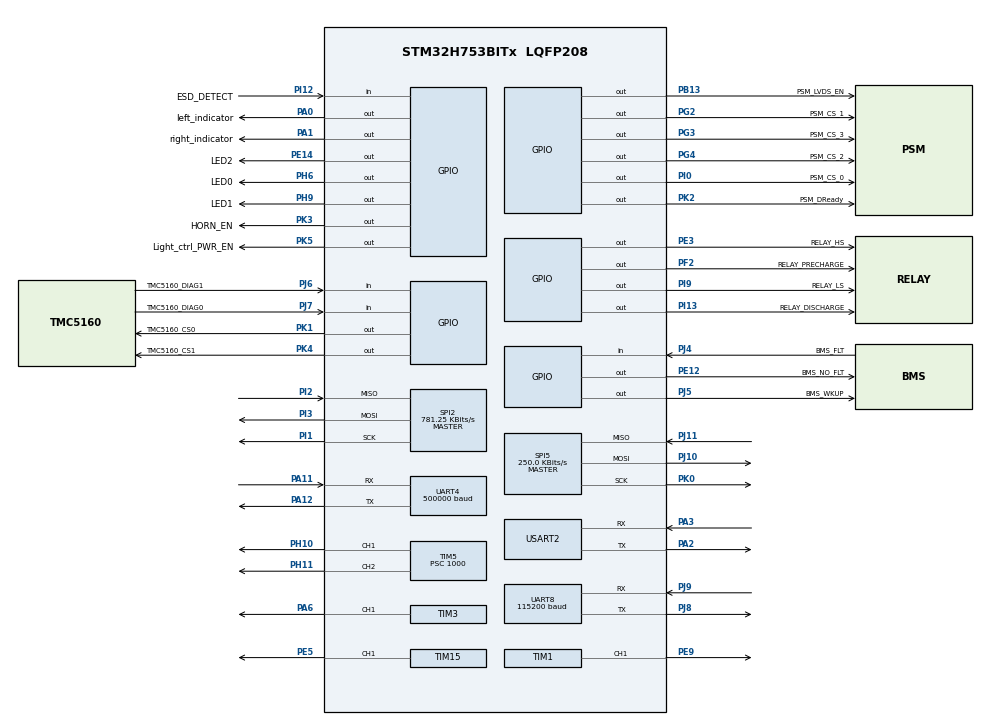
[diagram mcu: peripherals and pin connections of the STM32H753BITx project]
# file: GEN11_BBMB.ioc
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CRC.InputDataFormat=CRC_INPUTDATA_FORMAT_WORDS
CRC.InputDataInversionMode=CRC_INPUTDATA_INVERSION_NONE
CRC.OutputDataInversionMode=CRC_OUTPUTDATA_INVERSION_DISABLE
Dma.Request0=UART4_RX
Dma.Request1=UART4_TX
Dma.Request2=UART8_RX
Dma.Request3=UART8_TX
Dma.Request4=SPI2_RX
Dma.Request5=SPI2_TX
Dma.SPI2_RX.4.Direction=DMA_PERIPH_TO_MEMORY
Dma.SPI2_RX.4.EventEnable=DISABLE
Dma.SPI2_RX.4.FIFOMode=DMA_FIFOMODE_DISABLE
Dma.SPI2_RX.4.Instance=DMA1_Stream4
Dma.SPI2_RX.4.MemDataAlignment=DMA_MDATAALIGN_BYTE
Dma.SPI2_RX.4.MemInc=DMA_MINC_ENABLE
Dma.SPI2_RX.4.Mode=DMA_NORMAL
Dma.SPI2_RX.4.PeriphDataAlignment=DMA_PDATAALIGN_BYTE
Dma.SPI2_RX.4.PeriphInc=DMA_PINC_DISABLE
Dma.SPI2_RX.4.Polarity=HAL_DMAMUX_REQ_GEN_RISING
Dma.SPI2_RX.4.Priority=DMA_PRIORITY_LOW
Dma.SPI2_RX.4.RequestNumber=1
Dma.SPI2_RX.4.SignalID=NONE
Dma.SPI2_RX.4.SyncEnable=DISABLE
Dma.SPI2_RX.4.SyncPolarity=HAL_DMAMUX_SYNC_NO_EVENT
Dma.SPI2_RX.4.SyncRequestNumber=1
Dma.SPI2_RX.4.SyncSignalID=NONE
Dma.SPI2_TX.5.Direction=DMA_MEMORY_TO_PERIPH
Dma.SPI2_TX.5.EventEnable=DISABLE
Dma.SPI2_TX.5.FIFOMode=DMA_FIFOMODE_DISABLE
Dma.SPI2_TX.5.Instance=DMA1_Stream5
Dma.SPI2_TX.5.MemDataAlignment=DMA_MDATAALIGN_BYTE
Dma.SPI2_TX.5.MemInc=DMA_MINC_ENABLE
Dma.SPI2_TX.5.Mode=DMA_NORMAL
Dma.SPI2_TX.5.PeriphDataAlignment=DMA_PDATAALIGN_BYTE
Dma.SPI2_TX.5.PeriphInc=DMA_PINC_DISABLE
Dma.SPI2_TX.5.Polarity=HAL_DMAMUX_REQ_GEN_RISING
Dma.SPI2_TX.5.Priority=DMA_PRIORITY_LOW
Dma.SPI2_TX.5.RequestNumber=1
Dma.SPI2_TX.5.SignalID=NONE
Dma.SPI2_TX.5.SyncEnable=DISABLE
Dma.SPI2_TX.5.SyncPolarity=HAL_DMAMUX_SYNC_NO_EVENT
Dma.SPI2_TX.5.SyncRequestNumber=1
Dma.SPI2_TX.5.SyncSignalID=NONE
Dma.UART4_RX.0.Direction=DMA_PERIPH_TO_MEMORY
Dma.UART4_RX.0.EventEnable=DISABLE
Dma.UART4_RX.0.FIFOMode=DMA_FIFOMODE_DISABLE
Dma.UART4_RX.0.Instance=DMA1_Stream0
Dma.UART4_RX.0.MemDataAlignment=DMA_MDATAALIGN_BYTE
Dma.UART4_RX.0.MemInc=DMA_MINC_ENABLE
Dma.UART4_RX.0.Mode=DMA_CIRCULAR
Dma.UART4_RX.0.PeriphDataAlignment=DMA_PDATAALIGN_BYTE
Dma.UART4_RX.0.PeriphInc=DMA_PINC_DISABLE
Dma.UART4_RX.0.Polarity=HAL_DMAMUX_REQ_GEN_RISING
Dma.UART4_RX.0.Priority=DMA_PRIORITY_HIGH
Dma.UART4_RX.0.RequestNumber=1
Dma.UART4_RX.0.SignalID=NONE
Dma.UART4_RX.0.SyncEnable=DISABLE
Dma.UART4_RX.0.SyncPolarity=HAL_DMAMUX_SYNC_NO_EVENT
Dma.UART4_RX.0.SyncRequestNumber=1
Dma.UART4_RX.0.SyncSignalID=NONE
Dma.UART4_TX.1.Direction=DMA_MEMORY_TO_PERIPH
Dma.UART4_TX.1.EventEnable=DISABLE
Dma.UART4_TX.1.FIFOMode=DMA_FIFOMODE_DISABLE
Dma.UART4_TX.1.Instance=DMA1_Stream1
Dma.UART4_TX.1.MemDataAlignment=DMA_MDATAALIGN_BYTE
Dma.UART4_TX.1.MemInc=DMA_MINC_ENABLE
Dma.UART4_TX.1.Mode=DMA_NORMAL
Dma.UART4_TX.1.PeriphDataAlignment=DMA_PDATAALIGN_BYTE
Dma.UART4_TX.1.PeriphInc=DMA_PINC_DISABLE
Dma.UART4_TX.1.Polarity=HAL_DMAMUX_REQ_GEN_RISING
Dma.UART4_TX.1.Priority=DMA_PRIORITY_MEDIUM
Dma.UART4_TX.1.RequestNumber=1
Dma.UART4_TX.1.SignalID=NONE
Dma.UART4_TX.1.SyncEnable=DISABLE
Dma.UART4_TX.1.SyncPolarity=HAL_DMAMUX_SYNC_NO_EVENT
Dma.UART4_TX.1.SyncRequestNumber=1
Dma.UART4_TX.1.SyncSignalID=NONE
Dma.UART8_RX.2.Direction=DMA_PERIPH_TO_MEMORY
Dma.UART8_RX.2.EventEnable=DISABLE
Dma.UART8_RX.2.FIFOMode=DMA_FIFOMODE_DISABLE
Dma.UART8_RX.2.Instance=DMA1_Stream2
Dma.UART8_RX.2.MemDataAlignment=DMA_MDATAALIGN_BYTE
Dma.UART8_RX.2.MemInc=DMA_MINC_ENABLE
Dma.UART8_RX.2.Mode=DMA_CIRCULAR
Dma.UART8_RX.2.PeriphDataAlignment=DMA_PDATAALIGN_BYTE
Dma.UART8_RX.2.PeriphInc=DMA_PINC_DISABLE
Dma.UART8_RX.2.Polarity=HAL_DMAMUX_REQ_GEN_RISING
Dma.UART8_RX.2.Priority=DMA_PRIORITY_HIGH
Dma.UART8_RX.2.RequestNumber=1
Dma.UART8_RX.2.SignalID=NONE
Dma.UART8_RX.2.SyncEnable=DISABLE
Dma.UART8_RX.2.SyncPolarity=HAL_DMAMUX_SYNC_NO_EVENT
Dma.UART8_RX.2.SyncRequestNumber=1
Dma.UART8_RX.2.SyncSignalID=NONE
Dma.UART8_TX.3.Direction=DMA_MEMORY_TO_PERIPH
Dma.UART8_TX.3.EventEnable=DISABLE
Dma.UART8_TX.3.FIFOMode=DMA_FIFOMODE_DISABLE
Dma.UART8_TX.3.Instance=DMA1_Stream3
Dma.UART8_TX.3.MemDataAlignment=DMA_MDATAALIGN_BYTE
Dma.UART8_TX.3.MemInc=DMA_MINC_ENABLE
Dma.UART8_TX.3.Mode=DMA_NORMAL
Dma.UART8_TX.3.PeriphDataAlignment=DMA_PDATAALIGN_BYTE
Dma.UART8_TX.3.PeriphInc=DMA_PINC_DISABLE
Dma.UART8_TX.3.Polarity=HAL_DMAMUX_REQ_GEN_RISING
Dma.UART8_TX.3.Priority=DMA_PRIORITY_MEDIUM
Dma.UART8_TX.3.RequestNumber=1
Dma.UART8_TX.3.SignalID=NONE
Dma.UART8_TX.3.SyncEnable=DISABLE
Dma.UART8_TX.3.SyncPolarity=HAL_DMAMUX_SYNC_NO_EVENT
Dma.UART8_TX.3.SyncRequestNumber=1
Dma.UART8_TX.3.SyncSignalID=NONE
FREERTOS.INCLUDE_vTaskDelayUntil=1
FREERTOS.MEMORY_ALLOCATION=2
FREERTOS.Tasks01=defaultTask,0,128,StartDefaultTask,Default,NULL,Static,defaultTaskBuffer,defaultTaskControlBlock
FREERTOS.configTIMER_TASK_PRIORITY=5
FREERTOS.configTOTAL_HEAP_SIZE=40000
FREERTOS.configUSE_NEWLIB_REENTRANT=1
FREERTOS.configUSE_TIMERS=1
Mcu.Family=STM32H7
Mcu.Name=STM32H753BITx
Mcu.Package=LQFP208
NVIC.DMA1_Stream0_IRQn=true\:5\:0\:false\:false\:true\:true\:false\:true\:true
NVIC.DMA1_Stream1_IRQn=true\:5\:0\:false\:false\:true\:true\:false\:true\:true
NVIC.DMA1_Stream2_IRQn=true\:5\:0\:false\:false\:true\:true\:false\:true\:true
NVIC.DMA1_Stream3_IRQn=true\:5\:0\:false\:false\:true\:true\:false\:true\:true
NVIC.DMA1_Stream4_IRQn=true\:5\:0\:false\:false\:true\:true\:false\:true\:true
NVIC.DMA1_Stream5_IRQn=true\:5\:0\:false\:false\:true\:true\:false\:true\:true
NVIC.PriorityGroup=NVIC_PRIORITYGROUP_4
NVIC.SPI2_IRQn=true\:5\:0\:false\:false\:true\:true\:false\:true\:true
NVIC.SPI5_IRQn=true\:5\:0\:false\:false\:true\:true\:true\:true\:true
NVIC.TIM6_DAC_IRQn=true\:15\:0\:false\:false\:true\:false\:false\:true\:true
NVIC.TIM7_IRQn=true\:5\:0\:false\:false\:true\:true\:true\:true\:true
NVIC.TimeBase=TIM6_DAC_IRQn
NVIC.TimeBaseIP=TIM6
NVIC.UART4_IRQn=true\:5\:0\:false\:false\:true\:true\:true\:true\:true
NVIC.UART8_IRQn=true\:5\:0\:false\:false\:true\:true\:true\:true\:true
PA0.GPIO_Label=left_indicator
PA0.Signal=GPIO_Output
PA1.GPIO_Label=right_indicator
PA1.Signal=GPIO_Output
PA11.Mode=Asynchronous
PA11.Signal=UART4_RX
PA12.Mode=Asynchronous
PA12.Signal=UART4_TX
PA13\ (JTMS/SWDIO).Mode=Serial_Wire
PA13\ (JTMS/SWDIO).Signal=DEBUG_JTMS-SWDIO
PA14\ (JTCK/SWCLK).Mode=Serial_Wire
PA14\ (JTCK/SWCLK).Signal=DEBUG_JTCK-SWCLK
PA2.Mode=Asynchronous
PA2.Signal=USART2_TX
PA3.Mode=Asynchronous
PA3.Signal=USART2_RX
PA6.Signal=S_TIM3_CH1
PB13.GPIO_Label=PSM_LVDS_EN
PB13.Signal=GPIO_Output
PE12.GPIO_Label=BMS_NO_FLT
PE12.Signal=GPIO_Output
PE14.GPIO_Label=LED2
PE14.Signal=GPIO_Output
PE3.GPIO_Label=RELAY_HS
PE3.Signal=GPIO_Output
PE5.Signal=S_TIM15_CH1
PE9.Signal=S_TIM1_CH1
PF2.GPIO_Label=RELAY_PRECHARGE
PF2.Signal=GPIO_Output
PG2.GPIO_Label=PSM_CS_1
PG2.Signal=GPIO_Output
PG3.GPIO_Label=PSM_CS_3
PG3.Signal=GPIO_Output
PG4.GPIO_Label=PSM_CS_2
PG4.Signal=GPIO_Output
PH0-OSC_IN\ (PH0).Mode=HSE-External-Oscillator
PH0-OSC_IN\ (PH0).Signal=RCC_OSC_IN
PH1-OSC_OUT\ (PH1).Mode=HSE-External-Oscillator
PH1-OSC_OUT\ (PH1).Signal=RCC_OSC_OUT
PH10.Signal=S_TIM5_CH1
PH11.Signal=S_TIM5_CH2
PH6.GPIO_Label=LED0
PH6.Signal=GPIO_Output
PH9.GPIO_Label=LED1
PH9.Signal=GPIO_Output
PI0.GPIO_Label=PSM_CS_0
PI0.Signal=GPIO_Output
PI1.Mode=Full_Duplex_Master
PI1.Signal=SPI2_SCK
PI12.GPIO_Label=ESD_DETECT
PI12.Signal=GPIO_Input
PI13.GPIO_Label=RELAY_DISCHARGE
PI13.GPIO_PuPd=GPIO_PULLDOWN
PI13.Signal=GPIO_Output
PI2.Mode=Full_Duplex_Master
PI2.Signal=SPI2_MISO
PI3.Mode=Full_Duplex_Master
PI3.Signal=SPI2_MOSI
PI9.GPIO_Label=RELAY_LS
PI9.Signal=GPIO_Output
PJ10.Mode=Full_Duplex_Master
PJ10.Signal=SPI5_MOSI
PJ11.Mode=Full_Duplex_Master
PJ11.Signal=SPI5_MISO
PJ4.GPIO_Label=BMS_FLT
PJ4.Signal=GPIO_Input
PJ5.GPIO_Label=BMS_WKUP
PJ5.Signal=GPIO_Output
PJ6.GPIO_Label=TMC5160_DIAG1
PJ6.Signal=GPIO_Input
PJ7.GPIO_Label=TMC5160_DIAG0
PJ7.Signal=GPIO_Input
PJ8.Mode=Asynchronous
PJ8.Signal=UART8_TX
PJ9.Mode=Asynchronous
PJ9.Signal=UART8_RX
PK0.Mode=Full_Duplex_Master
PK0.Signal=SPI5_SCK
PK1.GPIO_Label=TMC5160_CS0
PK1.Signal=GPIO_Output
PK2.GPIO_Label=PSM_DReady
PK2.Signal=GPIO_Output
PK3.GPIO_Label=HORN_EN
PK3.GPIO_PuPd=GPIO_PULLDOWN
PK3.Signal=GPIO_Output
PK4.GPIO_Label=TMC5160_CS1
PK4.Signal=GPIO_Output
PK5.GPIO_Label=Light_ctrl_PWR_EN
PK5.Signal=GPIO_Output
ProjectManager.HeapSize=0x200
ProjectManager.StackSize=0x400
ProjectManager.TargetToolchain=STM32CubeIDE
RCC.ADCFreq_Value=50390625
RCC.APB1Freq_Value=16000000
RCC.APB2Freq_Value=16000000
RCC.APB3Freq_Value=32000000
RCC.APB4Freq_Value=32000000
RCC.CortexFreq_Value=64000000
RCC.D2PPRE1=RCC_APB1_DIV2
RCC.D2PPRE2=RCC_APB2_DIV2
RCC.DATA_CACHE_ENABLE=1
RCC.DIVM1=2
RCC.DIVN1=16
RCC.DIVQ1=4
RCC.HCLKFreq_Value=32000000
RCC.HPRE=RCC_HCLK_DIV2
RCC.HSE_VALUE=25000000
RCC.INSTRUCTION_CACHE_ENABLE=1
RCC.MSIAutoCalibration=DISABLED
RCC.MSICalibrationValue=0
RCC.PLL1_VCI_Range-AdvancedSettings=RCC_PLL1VCIRANGE_0
RCC.PLL2FRACN=0
RCC.PLL2_VCI_Range-AdvancedSettings=RCC_PLL2VCIRANGE_0
RCC.PLL3FRACN=0
RCC.PLLFRACN=0
RCC.PLLSourceVirtual=RCC_PLLSOURCE_HSE
RCC.PREFETCH_ENABLE=0
RCC.SYSCLKFreq_VALUE=64000000
RCC.USBFreq_Value=50000000
SH.S_TIM15_CH1.0=TIM15_CH1,PWM Generation1 CH1
SH.S_TIM1_CH1.0=TIM1_CH1,PWM Generation1 CH1
SH.S_TIM3_CH1.0=TIM3_CH1,PWM Generation1 CH1
SH.S_TIM5_CH1.0=TIM5_CH1,PWM Generation1 CH1
SH.S_TIM5_CH2.0=TIM5_CH2,PWM Generation2 CH2
SPI2.BaudRatePrescaler=SPI_BAUDRATEPRESCALER_64
SPI2.CLKPhase=SPI_PHASE_2EDGE
SPI2.CLKPolarity=SPI_POLARITY_LOW
SPI2.CalculateBaudRate=781.25 KBits/s
SPI2.DataSize=SPI_DATASIZE_8BIT
SPI2.Direction=SPI_DIRECTION_2LINES
SPI2.Mode=SPI_MODE_MASTER
SPI2.VirtualType=VM_MASTER
SPI5.BaudRatePrescaler=SPI_BAUDRATEPRESCALER_64
SPI5.CLKPhase=SPI_PHASE_2EDGE
SPI5.CLKPolarity=SPI_POLARITY_HIGH
SPI5.CalculateBaudRate=250.0 KBits/s
SPI5.DataSize=SPI_DATASIZE_8BIT
SPI5.Direction=SPI_DIRECTION_2LINES
SPI5.Mode=SPI_MODE_MASTER
SPI5.VirtualType=VM_MASTER
TIM1.AutoReloadPreload=TIM_AUTORELOAD_PRELOAD_ENABLE
TIM1.Channel-PWM\ Generation1\ CH1=TIM_CHANNEL_1
TIM1.Period=13552
TIM1.Prescaler=1000
TIM1.TIM_MasterOutputTrigger=TIM_TRGO_OC1REF
TIM15.Channel-PWM\ Generation1\ CH1=TIM_CHANNEL_1
TIM2.AutoReloadPreload=TIM_AUTORELOAD_PRELOAD_ENABLE
TIM2.Period=1600
TIM2.Prescaler=1000
TIM3.AutoReloadPreload=TIM_AUTORELOAD_PRELOAD_ENABLE
TIM3.Channel-PWM\ Generation1\ CH1=TIM_CHANNEL_1
TIM3.Period=6400
TIM3.Prescaler=1000
TIM3.Pulse-PWM\ Generation1\ CH1=0
TIM5.AutoReloadPreload=TIM_AUTORELOAD_PRELOAD_ENABLE
TIM5.Channel-PWM\ Generation1\ CH1=TIM_CHANNEL_1
TIM5.Channel-PWM\ Generation2\ CH2=TIM_CHANNEL_2
TIM5.Period=1600
TIM5.Prescaler=1000
TIM5.Pulse-PWM\ Generation1\ CH1=0
TIM7.AutoReloadPreload=TIM_AUTORELOAD_PRELOAD_ENABLE
TIM7.Period=1000
TIM7.Prescaler=40000
UART4.BaudRate=500000
UART8.BaudRate=115200
USART2.VirtualMode-Asynchronous=VM_ASYNC
VP_CRC_VS_CRC.Mode=CRC_Activate
VP_FREERTOS_VS_CMSIS_V1.Mode=CMSIS_V1
VP_SYS_VS_tim6.Mode=TIM6
VP_TIM2_VS_ClockSourceITR.Mode=TriggerSource_ITR0
VP_TIM2_VS_ControllerModeGated.Mode=Gated Mode
VP_TIM3_VS_ClockSourceITR.Mode=TriggerSource_ITR2
VP_TIM3_VS_ControllerModeGated.Mode=Gated Mode
VP_TIM7_VS_ClockSourceINT.Mode=Enable_Timer
board=custom

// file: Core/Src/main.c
/* USER CODE BEGIN Header */
/**
  ******************************************************************************
  * @file           : main.c
  * @brief          : Main program body
  ******************************************************************************
  * @attention
  *
  * Copyright (c) 2022 STMicroelectronics.
  * All rights reserved.
  *
  * This software is licensed under terms that can be found in the LICENSE file
  * in the root directory of this software component.
  * If no LICENSE file comes with this software, it is provided AS-IS.
  *
  ******************************************************************************
  */
/* USER CODE END Header */
#include "main.h"
#include "cmsis_os.h"

/* USER CODE BEGIN Includes */
#include "stdbool.h"
#include "buart.h"
#include "btcp.h"
#include "protocol_ids.h"
#include "bmisc.h"
#include "newpsm.h"
#include "h7Boot.h"
#include "TMC5160_driver.h"
#include "lights.h"
#include <stdio.h>
#include <math.h>
#include "battery_config.h"
#include "cQueue.h"
/* USER CODE END Includes */

/* USER CODE BEGIN PD */
#define BMS_CONNECTION_EXPIRY_THRESHOLD 2500

#define BATT_OVERCURRENT_CNT_THRESHOLD 5
#define BATT_OVERCURRENT_CNT_RESET_TIME 1000 // 1000 ms

#define BMS_READ_INTERVAL 		200		//(Other intervals defined in psm.h and btcp.h)
#define BMS_FLT_CHECK_INTERVAL 	10 		//Interval at which to read the BMS_FLT pin
#define PROTECTION_ENABLE 		1 		//Flag to enable (1) or disable (0) relay control

#define RELAY_STATE_TIMER_INTERVAL 	500 // Interval at which BBMB broadcasts the battery relay state in ms

#define OVERCURRENT_FILTER_SIZE  (MAX_ALLOWD_OVERCURRENT_TIME / PSM_SEND_INTERVAL)

/* USER CODE END PD */

CRC_HandleTypeDef hcrc;

SPI_HandleTypeDef hspi2;
SPI_HandleTypeDef hspi5;
DMA_HandleTypeDef hdma_spi2_rx;
DMA_HandleTypeDef hdma_spi2_tx;

TIM_HandleTypeDef htim1;
TIM_HandleTypeDef htim2;
TIM_HandleTypeDef htim3;
TIM_HandleTypeDef htim5;
TIM_HandleTypeDef htim7;
TIM_HandleTypeDef htim15;

UART_HandleTypeDef huart4;
UART_HandleTypeDef huart8;
UART_HandleTypeDef huart2;
DMA_HandleTypeDef hdma_uart4_rx;
DMA_HandleTypeDef hdma_uart4_tx;
DMA_HandleTypeDef hdma_uart8_rx;
DMA_HandleTypeDef hdma_uart8_tx;

osThreadId defaultTaskHandle;
uint32_t defaultTaskBuffer[ 128 ];
osStaticThreadDef_t defaultTaskControlBlock;
/* USER CODE BEGIN PV */

//--- COMMS ---//
B_tcpHandle_t btcp_bms_actual;
B_tcpHandle_t btcp_main_actual;

B_uartHandle_t* buart_main;
B_uartHandle_t* buart_bms;
B_tcpHandle_t* btcp_main = &btcp_main_actual;
B_tcpHandle_t* btcp_bms = &btcp_bms_actual;
uint8_t heartbeat[2] = {BBMB_HEARTBEAT_ID, 0};

//--- LIGHTS ---//
struct lights_stepper_ctrl lightsPeriph;
QueueHandle_t lightsCtrl = NULL;
uint8_t lightInstruction;
uint8_t efficiency_mode_on = 1;
uint8_t current_speed_kph;
float DRL_BRIGHTNESS_DIM = 0.1;
uint8_t left_indicator_on = 0;
uint8_t right_indicator_on = 0;
uint8_t hazard_on = 0;

//--- PSM ---//
struct PSM_P psmPeriph;
float battery_current = 0;
//double voltageCurrent_LV[2] = {0};
//double voltageCurrent_HV[2] = {0};

struct PSM_FIR_Filter psmFilter;
float PSM_FIR_HV_Voltage[PSM_FIR_FILTER_SAMPLING_FREQ_BBMB] = {0};
float PSM_FIR_HV_Current[PSM_FIR_FILTER_SAMPLING_FREQ_BBMB] = {0};

//--- RELAYS ---//
struct relay_periph relay;
QueueHandle_t relayCtrl = NULL;
uint8_t relayCtrlMessage;

//--- BMS ---//
int BMS_requesting_from = -1; //Holds which BMS we are requesting data from (needs initial value >5)
uint8_t BMS_data_received[3] = {RECEIVED, RECEIVED, RECEIVED}; //Holds whether we received voltage, temperature and SoC for the current BMS
uint32_t BMS_tick_count_last_packet;

//--- Battery ---/
uint8_t batteryState = HEALTHY;
uint8_t batteryFaultType = BATTERY_FAULT_NONE; //Default to fault type 4, which doesn't correspond to any fault
uint8_t batteryFaultCell = 0;
uint8_t batteryFaultTherm = 0;
uint8_t battery_overvoltage = 0;
uint8_t battery_undervoltage = 0;
uint8_t battery_overtemperature = 0;
uint8_t battery_undertemperature = 0;
uint8_t battery_overcurrent = 0;
uint8_t motor_overtemperature = 0;

uint8_t fault_enable = 1;

float motor_temperature = 0;
//--- MOTOR ---//
typedef enum {
	OFF,
	PEDAL,
	CRUISE,
	REGEN,
	STANDBY,
	REGEN_NA
} MOTORSTATE;

uint8_t motorState = OFF;

float battery_cell_voltages[NUM_BATT_CELLS] = {[0 ... (NUM_BATT_CELLS-1)] = BATTERY_CELL_VOLTAGES_INITIAL_VALUE};
float battery_temperatures[NUM_BATT_TEMP_SENSORS] = {[0 ... (NUM_BATT_TEMP_SENSORS-1)] = BATTERY_TEMPERATURES_INITIAL_VALUE};

//--- Discharge test ---//
float cellUnderTestVoltage = -1;
float cellUnderTestSOC = -1;

// Special filtering
typedef struct StaticFloatQueue {
	float vals[OVERCURRENT_FILTER_SIZE];
	Queue_t q;
}StaticFloatQueue;

static void sfq_init(StaticFloatQueue* this)
{
	q_init_static(
			&this->q,
			sizeof(float),
			OVERCURRENT_FILTER_SIZE,
			FIFO,
			true, // Overwrite old values (so we only need to call push() and no need to pop())
			this->vals,
			sizeof(this->vals)
		);
}
StaticFloatQueue battery_overcurrent_queue, motor_overcurrent_queue, array_overcurrent_queue;

static bool sfq_push(StaticFloatQueue* this, float val)
{
	return q_push(&this->q, &val);
}

static bool sfq_peek_idx(StaticFloatQueue* this, float* ret_val, int idx)
{
	return q_peekIdx(&this->q, ret_val, idx);
}

static float sfq_get_avg(StaticFloatQueue* this)
{
	float total_past_vals = 0;
	int num_past_vals = 0;
	for (int idx = 0; idx < OVERCURRENT_FILTER_SIZE; idx++){
		float past_val;
		if (sfq_peek_idx(this, &past_val, idx)) { // evaluates to true if val is available
			num_past_vals++;
			total_past_vals += past_val;
		}
	}
	return total_past_vals / (float)num_past_vals;
}

/* USER CODE END PV */

void SystemClock_Config(void);
static void MX_GPIO_Init(void);
static void MX_DMA_Init(void);
static void MX_TIM1_Init(void);
static void MX_TIM5_Init(void);
static void MX_TIM2_Init(void);
static void MX_SPI2_Init(void);
static void MX_SPI5_Init(void);
static void MX_CRC_Init(void);
static void MX_TIM3_Init(void);
static void MX_USART2_UART_Init(void);
static void MX_TIM7_Init(void);
static void MX_UART4_Init(void);
static void MX_UART8_Init(void);
static void MX_TIM15_Init(void);
void StartDefaultTask(void const * argument);

/* USER CODE BEGIN PFP */
static void lightsTask(void * argument);
static void relayTask(void * argument);
void PSMTaskHandler(void * parameters);
void measurementSender(void* p);
void HeartbeatHandler(TimerHandle_t xTimer);
void battery_faulted_routine(/*uint8_t fault_type, uint8_t fault_cell, uint8_t fault_thermistor*/);
void battery_unfaulted_routine();
void RelayStateTimer(TimerHandle_t xTimer);
void dischargeTest(TimerHandle_t xTimer);
void fault_state_setter();
void indicatorTimer(TimerHandle_t xTimer);

/* USER CODE END PFP */

int main(void)
{

  /* MCU Configuration--------------------------------------------------------*/

  /* Reset of all peripherals, Initializes the Flash interface and the Systick. */
  HAL_Init();

  /* Configure the system clock */
  SystemClock_Config();

  /* Initialize all configured peripherals */
  MX_GPIO_Init();
  MX_DMA_Init();
  MX_TIM1_Init();
  MX_TIM5_Init();
  MX_TIM2_Init();
  MX_SPI2_Init();
  MX_SPI5_Init();
  MX_CRC_Init();
  MX_TIM3_Init();
  MX_USART2_UART_Init();
  MX_TIM7_Init();
  MX_UART4_Init();
  MX_UART8_Init();
  MX_TIM15_Init();
  /* USER CODE BEGIN 2 */
  //--- MCU OK LED ---//
  NVIC_EnableIRQ(TIM7_IRQn);
  HAL_TIM_Base_Start_IT((TIM_HandleTypeDef*) &htim7); //Blink LED to show that CPU is still alive

  HAL_Delay(1500);

  sfq_init(&battery_overcurrent_queue);
  sfq_init(&motor_overcurrent_queue);
  sfq_init(&array_overcurrent_queue);

  //--- PSM ---//

  psmPeriph.CSPin = PSM_CS_0_Pin;
  psmPeriph.CSPort = PSM_CS_0_GPIO_Port;
  psmPeriph.LVDSPort = PSM_LVDS_EN_GPIO_Port;
  psmPeriph.LVDSPin = PSM_LVDS_EN_Pin;
  psmPeriph.motherboard = BBMB_PSM;

  PSM_init(&psmPeriph, &hspi2, &huart2);
  PSM_FIR_Init(&psmFilter);

  test_config(&psmPeriph, &hspi2, &huart2);

  psmFilter.buf_voltage = PSM_FIR_HV_Voltage;
  psmFilter.buf_current = PSM_FIR_HV_Current;
  psmFilter.buf_size = PSM_FIR_FILTER_SAMPLING_FREQ_BBMB;
//  if (configPSM(&psmPeriph, &hspi2, &huart2, "12", 2000) == -1){ //2000ms timeout
//	  HAL_GPIO_WritePin(LED0_GPIO_Port, LED0_Pin, GPIO_PIN_SET); //Turn on red LED as a warning
//  }

//  double PSM_data[2];
//  PSMRead(&psmPeriph, &hspi2, &huart2, 1, 2, 2, PSM_data, 2);
//  PSMRead(&psmPeriph, &hspi2, &huart2, 1, 2, 1, PSM_data, 2);

  //--- RDB ---//
  relay.DISCHARGE_GPIO_Port = RELAY_DISCHARGE_GPIO_Port;
  relay.DISCHARGE_Pin = RELAY_DISCHARGE_Pin;
  relay.GND_SIG_GPIO_Port = RELAY_LS_GPIO_Port;
  relay.GND_SIG_Pin = RELAY_LS_Pin;
  relay.ON_SIG_GPIO_Port = RELAY_HS_GPIO_Port;
  relay.ON_SIG_Pin = RELAY_HS_Pin;
  relay.PRE_SIG_GPIO_Port = RELAY_PRECHARGE_GPIO_Port;
  relay.PRE_SIG_Pin = RELAY_PRECHARGE_Pin;
  relay.battery_relay_state = OPEN; //Open battery relays at startup
  relay.array_relay_state = OPEN; //Assume array relays are opened until confirmation is recevied from PPTMB

  //--- LIGHTS ---//
  lightsPeriph.CSPin0 = TMC5160_CS0_Pin;
  lightsPeriph.CSPort0 = TMC5160_CS0_GPIO_Port;
  lightsPeriph.CSPin1 = TMC5160_CS1_Pin;
  lightsPeriph.CSPort1 = TMC5160_CS1_GPIO_Port;

  lightsPeriph.PWR_EN_Pin = Light_ctrl_PWR_EN_Pin;
  lightsPeriph.PWR_EN_Port = GPIOK;

  lightsPeriph.TMC5160_SPI = &hspi5;

  lightsPeriph.right_ind_TIM = &htim2;
  lightsPeriph.right_ind_CH = TIM_CHANNEL_2;
  lightsPeriph.left_ind_TIM = &htim2;
  lightsPeriph.left_ind_CH = TIM_CHANNEL_1;
  lightsPeriph.ind_master_TIM = &htim1;
  lightsPeriph.ind_master_CH = TIM_CHANNEL_1;
  lightsPeriph.BRK_TIM = &htim5;
  lightsPeriph.BRK_CH = TIM_CHANNEL_2;
  lightsPeriph.DRL_TIM = &htim5;
  lightsPeriph.DRL_CH = TIM_CHANNEL_1;
  lightsPeriph.FLT_TIM = &htim3;
  lightsPeriph.FLT_CH = TIM_CHANNEL_1;
  lightsPeriph.FLT_master_TIM = &htim15;
  lightsPeriph.FLT_master_CH = TIM_CHANNEL_1;
  lightsPeriph.hazard_state = LIGHTS_OFF;
  lightsPeriph.right_indicator_state = LIGHTS_OFF;
  lightsPeriph.left_indicator_state = LIGHTS_OFF;

  //Initial state of lights: all off
//  turn_off_indicators(&lightsPeriph, LEFT);
//  turn_off_indicators(&lightsPeriph, RIGHT);
  turn_off_DRL(&lightsPeriph);
  turn_off_brake_lights(&lightsPeriph);
  turn_off_fault_indicator(&lightsPeriph);
//  turn_off_hazard_lights(&lightsPeriph);

//  lightsPeriph.ind_master_TIM->Instance->ARR = 25599; //Period of ~0.8s (~75 blinks per second) assuming 32MHz clock and 999 prescaler.
//  lightsPeriph.ind_master_TIM->Instance->CCR1 = 12800; //On-time of 50%
//  HAL_TIM_PWM_Start(lightsPeriph.ind_master_TIM, lightsPeriph.ind_master_CH);

  //--- COMMS ---//
  buart_main = B_uartStart(&huart4);
  btcp_main = B_tcpStart(BBMB_ID, &buart_main, buart_main, 1, &hcrc);
  buart_bms = B_uartStart(&huart8);
  btcp_bms = B_tcpStart(BBMB_ID, &buart_bms, buart_bms, 1, &hcrc);

  //--- FREERTOS ---//
  lightsCtrl = xQueueCreate(16, sizeof(uint8_t)); //Holds instruction for lights control
  relayCtrl = xQueueCreate(8, sizeof(uint8_t)); //Holds instruction to open (1) or close relay (2)

  configASSERT(xTaskCreate(lightsTask, "LightsTask", 1024, ( void * ) 1, 4, NULL));
  configASSERT(xTaskCreate(relayTask, "relayCtrl", 1024, ( void * ) 1, 4, NULL));

  configASSERT(xTimerStart(xTimerCreate("HeartbeatHandler",  pdMS_TO_TICKS(HEARTBEAT_INTERVAL / 2), pdTRUE, (void *)0, HeartbeatHandler), 0)); //Heartbeat handler
  configASSERT(xTimerStart(xTimerCreate("dischargeTest",  pdMS_TO_TICKS(250), pdTRUE, (void *)0, dischargeTest), 0));
  configASSERT(xTimerStart(xTimerCreate("relayStateTimer",  pdMS_TO_TICKS(RELAY_STATE_TIMER_INTERVAL), pdTRUE, (void *)0, RelayStateTimer), 0));
  configASSERT(xTimerStart(xTimerCreate("indicatorTimer",  pdMS_TO_TICKS(250), pdTRUE, (void *)0, indicatorTimer), 0));

  //--- RELAYS ---//
  if (PROTECTION_ENABLE == 0){ //No protection, so close relays immediately
	  //Close battery relays
	  relayCtrlMessage = 2;
	  xQueueSend(relayCtrl, &relayCtrlMessage, 10);
  }

  //--- BATTERY ---//
  HAL_GPIO_WritePin(relay.DISCHARGE_GPIO_Port, relay.DISCHARGE_Pin, GPIO_PIN_SET); //Turn off HV discharge
  HAL_GPIO_WritePin(BMS_NO_FLT_GPIO_Port, BMS_NO_FLT_Pin, GPIO_PIN_SET); //Turn off BPS fault LED on driver's panel and activate Vicor 12V
  HAL_GPIO_WritePin(BMS_WKUP_GPIO_Port, BMS_WKUP_Pin, GPIO_PIN_SET); //Power BMS from battery module instead of supplemental battery

  /* USER CODE END 2 */

  /* USER CODE BEGIN RTOS_QUEUES */
  /* add queues, ... */
#ifdef DEFAULT_TASK

  /* USER CODE END RTOS_QUEUES */

  /* Create the thread(s) */
  /* definition and creation of defaultTask */
  osThreadStaticDef(defaultTask, StartDefaultTask, osPriorityNormal, 0, 128, defaultTaskBuffer, &defaultTaskControlBlock);
  defaultTaskHandle = osThreadCreate(osThread(defaultTask), NULL);

  /* USER CODE BEGIN RTOS_THREADS */
#endif
  /* add threads, ... */
  BaseType_t status;
  TaskHandle_t PSM_handle;
  status = xTaskCreate(PSMTaskHandler,  //Function that implements the task.
						"PSMTask",  // Text name for the task.
						200, 		 // 200 words *4(bytes/word) = 800 bytes allocated for task's stack
						"none",  // Parameter passed into the task.
						4,  // Priority at which the task is created.
						&PSM_handle  // Used to pass out the created task's handle.
									);
  configASSERT(status == pdPASS);// Error checking

  TaskHandle_t measurementSenderHandle;
  status = xTaskCreate(measurementSender,  //Function that implements the task.
						"measurementSender",  // Text name for the task.
						200, 		 // 200 words *4(bytes/word) = 800 bytes allocated for task's stack
						"none",  // Parameter passed into the task.
						4,  // Priority at which the task is created.
						&measurementSenderHandle  // Used to pass out the created task's handle.
									);
  configASSERT(status == pdPASS);// Error checking

//  TaskHandle_t fault_state_setter_handle;
//  status = xTaskCreate(fault_state_setter,  //Function that implements the task.
//						"measurementSender",  // Text name for the task.
//						200, 		 // 200 words *4(bytes/word) = 800 bytes allocated for task's stack
//						"none",  // Parameter passed into the task.
//						4,  // Priority at which the task is created.
//						&fault_state_setter_handle  // Used to pass out the created task's handle.
//									);
//  configASSERT(status == pdPASS);// Error checking

  /* USER CODE END RTOS_THREADS */

  /* Start scheduler */
  osKernelStart();

  /* We should never get here as control is now taken by the scheduler */
  /* Infinite loop */
  while (1)
  {

  }
}

void SystemClock_Config(void)
{
  RCC_OscInitTypeDef RCC_OscInitStruct = {0};
  RCC_ClkInitTypeDef RCC_ClkInitStruct = {0};

  /** Supply configuration update enable
  */
  HAL_PWREx_ConfigSupply(PWR_LDO_SUPPLY);
  /** Configure the main internal regulator output voltage
  */
  __HAL_PWR_VOLTAGESCALING_CONFIG(PWR_REGULATOR_VOLTAGE_SCALE3);

  while(!__HAL_PWR_GET_FLAG(PWR_FLAG_VOSRDY)) {}
  /** Initializes the RCC Oscillators according to the specified parameters
  * in the RCC_OscInitTypeDef structure.
  */
  RCC_OscInitStruct.OscillatorType = RCC_OSCILLATORTYPE_HSI|RCC_OSCILLATORTYPE_HSE;
  RCC_OscInitStruct.HSEState = RCC_HSE_ON;
  RCC_OscInitStruct.HSIState = RCC_HSI_DIV1;
  RCC_OscInitStruct.HSICalibrationValue = RCC_HSICALIBRATION_DEFAULT;
  RCC_OscInitStruct.PLL.PLLState = RCC_PLL_ON;
  RCC_OscInitStruct.PLL.PLLSource = RCC_PLLSOURCE_HSE;
  RCC_OscInitStruct.PLL.PLLM = 2;
  RCC_OscInitStruct.PLL.PLLN = 16;
  RCC_OscInitStruct.PLL.PLLP = 2;
  RCC_OscInitStruct.PLL.PLLQ = 4;
  RCC_OscInitStruct.PLL.PLLR = 2;
  RCC_OscInitStruct.PLL.PLLRGE = RCC_PLL1VCIRANGE_3;
  RCC_OscInitStruct.PLL.PLLVCOSEL = RCC_PLL1VCOWIDE;
  RCC_OscInitStruct.PLL.PLLFRACN = 0;
  if (HAL_RCC_OscConfig(&RCC_OscInitStruct) != HAL_OK)
  {
    Error_Handler();
  }
  /** Initializes the CPU, AHB and APB buses clocks
  */
  RCC_ClkInitStruct.ClockType = RCC_CLOCKTYPE_HCLK|RCC_CLOCKTYPE_SYSCLK
                              |RCC_CLOCKTYPE_PCLK1|RCC_CLOCKTYPE_PCLK2
                              |RCC_CLOCKTYPE_D3PCLK1|RCC_CLOCKTYPE_D1PCLK1;
  RCC_ClkInitStruct.SYSCLKSource = RCC_SYSCLKSOURCE_HSI;
  RCC_ClkInitStruct.SYSCLKDivider = RCC_SYSCLK_DIV1;
  RCC_ClkInitStruct.AHBCLKDivider = RCC_HCLK_DIV2;
  RCC_ClkInitStruct.APB3CLKDivider = RCC_APB3_DIV1;
  RCC_ClkInitStruct.APB1CLKDivider = RCC_APB1_DIV2;
  RCC_ClkInitStruct.APB2CLKDivider = RCC_APB2_DIV2;
  RCC_ClkInitStruct.APB4CLKDivider = RCC_APB4_DIV1;

  if (HAL_RCC_ClockConfig(&RCC_ClkInitStruct, FLASH_LATENCY_0) != HAL_OK)
  {
    Error_Handler();
  }
}

static void MX_CRC_Init(void)
{

  hcrc.Instance = CRC;
  hcrc.Init.DefaultPolynomialUse = DEFAULT_POLYNOMIAL_ENABLE;
  hcrc.Init.DefaultInitValueUse = DEFAULT_INIT_VALUE_ENABLE;
  hcrc.Init.InputDataInversionMode = CRC_INPUTDATA_INVERSION_NONE;
  hcrc.Init.OutputDataInversionMode = CRC_OUTPUTDATA_INVERSION_DISABLE;
  hcrc.InputDataFormat = CRC_INPUTDATA_FORMAT_WORDS;
  if (HAL_CRC_Init(&hcrc) != HAL_OK)
  {
    Error_Handler();
  }

}

static void MX_SPI2_Init(void)
{

  /* SPI2 parameter configuration*/
  hspi2.Instance = SPI2;
  hspi2.Init.Mode = SPI_MODE_MASTER;
  hspi2.Init.Direction = SPI_DIRECTION_2LINES;
  hspi2.Init.DataSize = SPI_DATASIZE_8BIT;
  hspi2.Init.CLKPolarity = SPI_POLARITY_LOW;
  hspi2.Init.CLKPhase = SPI_PHASE_2EDGE;
  hspi2.Init.NSS = SPI_NSS_SOFT;
  hspi2.Init.BaudRatePrescaler = SPI_BAUDRATEPRESCALER_64;
  hspi2.Init.FirstBit = SPI_FIRSTBIT_MSB;
  hspi2.Init.TIMode = SPI_TIMODE_DISABLE;
  hspi2.Init.CRCCalculation = SPI_CRCCALCULATION_DISABLE;
  hspi2.Init.CRCPolynomial = 0x0;
  hspi2.Init.NSSPMode = SPI_NSS_PULSE_ENABLE;
  hspi2.Init.NSSPolarity = SPI_NSS_POLARITY_LOW;
  hspi2.Init.FifoThreshold = SPI_FIFO_THRESHOLD_01DATA;
  hspi2.Init.TxCRCInitializationPattern = SPI_CRC_INITIALIZATION_ALL_ZERO_PATTERN;
  hspi2.Init.RxCRCInitializationPattern = SPI_CRC_INITIALIZATION_ALL_ZERO_PATTERN;
  hspi2.Init.MasterSSIdleness = SPI_MASTER_SS_IDLENESS_00CYCLE;
  hspi2.Init.MasterInterDataIdleness = SPI_MASTER_INTERDATA_IDLENESS_00CYCLE;
  hspi2.Init.MasterReceiverAutoSusp = SPI_MASTER_RX_AUTOSUSP_DISABLE;
  hspi2.Init.MasterKeepIOState = SPI_MASTER_KEEP_IO_STATE_DISABLE;
  hspi2.Init.IOSwap = SPI_IO_SWAP_DISABLE;
  if (HAL_SPI_Init(&hspi2) != HAL_OK)
  {
    Error_Handler();
  }

}

static void MX_SPI5_Init(void)
{

  /* SPI5 parameter configuration*/
  hspi5.Instance = SPI5;
  hspi5.Init.Mode = SPI_MODE_MASTER;
  hspi5.Init.Direction = SPI_DIRECTION_2LINES;
  hspi5.Init.DataSize = SPI_DATASIZE_8BIT;
  hspi5.Init.CLKPolarity = SPI_POLARITY_HIGH;
  hspi5.Init.CLKPhase = SPI_PHASE_2EDGE;
  hspi5.Init.NSS = SPI_NSS_SOFT;
  hspi5.Init.BaudRatePrescaler = SPI_BAUDRATEPRESCALER_64;
  hspi5.Init.FirstBit = SPI_FIRSTBIT_MSB;
  hspi5.Init.TIMode = SPI_TIMODE_DISABLE;
  hspi5.Init.CRCCalculation = SPI_CRCCALCULATION_DISABLE;
  hspi5.Init.CRCPolynomial = 0x0;
  hspi5.Init.NSSPMode = SPI_NSS_PULSE_ENABLE;
  hspi5.Init.NSSPolarity = SPI_NSS_POLARITY_LOW;
  hspi5.Init.FifoThreshold = SPI_FIFO_THRESHOLD_01DATA;
  hspi5.Init.TxCRCInitializationPattern = SPI_CRC_INITIALIZATION_ALL_ZERO_PATTERN;
  hspi5.Init.RxCRCInitializationPattern = SPI_CRC_INITIALIZATION_ALL_ZERO_PATTERN;
  hspi5.Init.MasterSSIdleness = SPI_MASTER_SS_IDLENESS_00CYCLE;
  hspi5.Init.MasterInterDataIdleness = SPI_MASTER_INTERDATA_IDLENESS_00CYCLE;
  hspi5.Init.MasterReceiverAutoSusp = SPI_MASTER_RX_AUTOSUSP_DISABLE;
  hspi5.Init.MasterKeepIOState = SPI_MASTER_KEEP_IO_STATE_DISABLE;
  hspi5.Init.IOSwap = SPI_IO_SWAP_DISABLE;
  if (HAL_SPI_Init(&hspi5) != HAL_OK)
  {
    Error_Handler();
  }

}

static void MX_TIM1_Init(void)
{

  TIM_MasterConfigTypeDef sMasterConfig = {0};
  TIM_OC_InitTypeDef sConfigOC = {0};
  TIM_BreakDeadTimeConfigTypeDef sBreakDeadTimeConfig = {0};

  htim1.Instance = TIM1;
  htim1.Init.Prescaler = 1000;
  htim1.Init.CounterMode = TIM_COUNTERMODE_UP;
  htim1.Init.Period = 13552;
  htim1.Init.ClockDivision = TIM_CLOCKDIVISION_DIV1;
  htim1.Init.RepetitionCounter = 0;
  htim1.Init.AutoReloadPreload = TIM_AUTORELOAD_PRELOAD_ENABLE;
  if (HAL_TIM_PWM_Init(&htim1) != HAL_OK)
  {
    Error_Handler();
  }
  sMasterConfig.MasterOutputTrigger = TIM_TRGO_OC1REF;
  sMasterConfig.MasterOutputTrigger2 = TIM_TRGO2_RESET;
  sMasterConfig.MasterSlaveMode = TIM_MASTERSLAVEMODE_DISABLE;
  if (HAL_TIMEx_MasterConfigSynchronization(&htim1, &sMasterConfig) != HAL_OK)
  {
    Error_Handler();
  }
  sConfigOC.OCMode = TIM_OCMODE_PWM1;
  sConfigOC.Pulse = 0;
  sConfigOC.OCPolarity = TIM_OCPOLARITY_HIGH;
  sConfigOC.OCNPolarity = TIM_OCNPOLARITY_HIGH;
  sConfigOC.OCFastMode = TIM_OCFAST_DISABLE;
  sConfigOC.OCIdleState = TIM_OCIDLESTATE_RESET;
  sConfigOC.OCNIdleState = TIM_OCNIDLESTATE_RESET;
  if (HAL_TIM_PWM_ConfigChannel(&htim1, &sConfigOC, TIM_CHANNEL_1) != HAL_OK)
  {
    Error_Handler();
  }
  sBreakDeadTimeConfig.OffStateRunMode = TIM_OSSR_DISABLE;
  sBreakDeadTimeConfig.OffStateIDLEMode = TIM_OSSI_DISABLE;
  sBreakDeadTimeConfig.LockLevel = TIM_LOCKLEVEL_OFF;
  sBreakDeadTimeConfig.DeadTime = 0;
  sBreakDeadTimeConfig.BreakState = TIM_BREAK_DISABLE;
  sBreakDeadTimeConfig.BreakPolarity = TIM_BREAKPOLARITY_HIGH;
  sBreakDeadTimeConfig.BreakFilter = 0;
  sBreakDeadTimeConfig.Break2State = TIM_BREAK2_DISABLE;
  sBreakDeadTimeConfig.Break2Polarity = TIM_BREAK2POLARITY_HIGH;
  sBreakDeadTimeConfig.Break2Filter = 0;
  sBreakDeadTimeConfig.AutomaticOutput = TIM_AUTOMATICOUTPUT_DISABLE;
  if (HAL_TIMEx_ConfigBreakDeadTime(&htim1, &sBreakDeadTimeConfig) != HAL_OK)
  {
    Error_Handler();
  }
  HAL_TIM_MspPostInit(&htim1);

}

static void MX_TIM2_Init(void)
{

  TIM_SlaveConfigTypeDef sSlaveConfig = {0};
  TIM_MasterConfigTypeDef sMasterConfig = {0};

  htim2.Instance = TIM2;
  htim2.Init.Prescaler = 1000;
  htim2.Init.CounterMode = TIM_COUNTERMODE_UP;
  htim2.Init.Period = 1600;
  htim2.Init.ClockDivision = TIM_CLOCKDIVISION_DIV1;
  htim2.Init.AutoReloadPreload = TIM_AUTORELOAD_PRELOAD_ENABLE;
  if (HAL_TIM_Base_Init(&htim2) != HAL_OK)
  {
    Error_Handler();
  }
  sSlaveConfig.SlaveMode = TIM_SLAVEMODE_GATED;
  sSlaveConfig.InputTrigger = TIM_TS_ITR0;
  if (HAL_TIM_SlaveConfigSynchro(&htim2, &sSlaveConfig) != HAL_OK)
  {
    Error_Handler();
  }
  sMasterConfig.MasterOutputTrigger = TIM_TRGO_RESET;
  sMasterConfig.MasterSlaveMode = TIM_MASTERSLAVEMODE_DISABLE;
  if (HAL_TIMEx_MasterConfigSynchronization(&htim2, &sMasterConfig) != HAL_OK)
  {
    Error_Handler();
  }

}

static void MX_TIM3_Init(void)
{

  TIM_SlaveConfigTypeDef sSlaveConfig = {0};
  TIM_MasterConfigTypeDef sMasterConfig = {0};
  TIM_OC_InitTypeDef sConfigOC = {0};

  htim3.Instance = TIM3;
  htim3.Init.Prescaler = 1000;
  htim3.Init.CounterMode = TIM_COUNTERMODE_UP;
  htim3.Init.Period = 6400;
  htim3.Init.ClockDivision = TIM_CLOCKDIVISION_DIV1;
  htim3.Init.AutoReloadPreload = TIM_AUTORELOAD_PRELOAD_ENABLE;
  if (HAL_TIM_Base_Init(&htim3) != HAL_OK)
  {
    Error_Handler();
  }
  if (HAL_TIM_PWM_Init(&htim3) != HAL_OK)
  {
    Error_Handler();
  }
  sSlaveConfig.SlaveMode = TIM_SLAVEMODE_GATED;
  sSlaveConfig.InputTrigger = TIM_TS_ITR2;
  if (HAL_TIM_SlaveConfigSynchro(&htim3, &sSlaveConfig) != HAL_OK)
  {
    Error_Handler();
  }
  sMasterConfig.MasterOutputTrigger = TIM_TRGO_RESET;
  sMasterConfig.MasterSlaveMode = TIM_MASTERSLAVEMODE_DISABLE;
  if (HAL_TIMEx_MasterConfigSynchronization(&htim3, &sMasterConfig) != HAL_OK)
  {
    Error_Handler();
  }
  sConfigOC.OCMode = TIM_OCMODE_PWM1;
  sConfigOC.Pulse = 0;
  sConfigOC.OCPolarity = TIM_OCPOLARITY_HIGH;
  sConfigOC.OCFastMode = TIM_OCFAST_DISABLE;
  if (HAL_TIM_PWM_ConfigChannel(&htim3, &sConfigOC, TIM_CHANNEL_1) != HAL_OK)
  {
    Error_Handler();
  }
  HAL_TIM_MspPostInit(&htim3);

}

static void MX_TIM5_Init(void)
{

  TIM_MasterConfigTypeDef sMasterConfig = {0};
  TIM_OC_InitTypeDef sConfigOC = {0};

  htim5.Instance = TIM5;
  htim5.Init.Prescaler = 1000;
  htim5.Init.CounterMode = TIM_COUNTERMODE_UP;
  htim5.Init.Period = 1600;
  htim5.Init.ClockDivision = TIM_CLOCKDIVISION_DIV1;
  htim5.Init.AutoReloadPreload = TIM_AUTORELOAD_PRELOAD_ENABLE;
  if (HAL_TIM_PWM_Init(&htim5) != HAL_OK)
  {
    Error_Handler();
  }
  sMasterConfig.MasterOutputTrigger = TIM_TRGO_RESET;
  sMasterConfig.MasterSlaveMode = TIM_MASTERSLAVEMODE_DISABLE;
  if (HAL_TIMEx_MasterConfigSynchronization(&htim5, &sMasterConfig) != HAL_OK)
  {
    Error_Handler();
  }
  sConfigOC.OCMode = TIM_OCMODE_PWM1;
  sConfigOC.Pulse = 0;
  sConfigOC.OCPolarity = TIM_OCPOLARITY_HIGH;
  sConfigOC.OCFastMode = TIM_OCFAST_DISABLE;
  if (HAL_TIM_PWM_ConfigChannel(&htim5, &sConfigOC, TIM_CHANNEL_1) != HAL_OK)
  {
    Error_Handler();
  }
  if (HAL_TIM_PWM_ConfigChannel(&htim5, &sConfigOC, TIM_CHANNEL_2) != HAL_OK)
  {
    Error_Handler();
  }
  HAL_TIM_MspPostInit(&htim5);

}

static void MX_TIM7_Init(void)
{

  TIM_MasterConfigTypeDef sMasterConfig = {0};

  htim7.Instance = TIM7;
  htim7.Init.Prescaler = 40000;
  htim7.Init.CounterMode = TIM_COUNTERMODE_UP;
  htim7.Init.Period = 1000;
  htim7.Init.AutoReloadPreload = TIM_AUTORELOAD_PRELOAD_ENABLE;
  if (HAL_TIM_Base_Init(&htim7) != HAL_OK)
  {
    Error_Handler();
  }
  sMasterConfig.MasterOutputTrigger = TIM_TRGO_RESET;
  sMasterConfig.MasterSlaveMode = TIM_MASTERSLAVEMODE_DISABLE;
  if (HAL_TIMEx_MasterConfigSynchronization(&htim7, &sMasterConfig) != HAL_OK)
  {
    Error_Handler();
  }

}

static void MX_TIM15_Init(void)
{

  TIM_MasterConfigTypeDef sMasterConfig = {0};
  TIM_OC_InitTypeDef sConfigOC = {0};
  TIM_BreakDeadTimeConfigTypeDef sBreakDeadTimeConfig = {0};

  htim15.Instance = TIM15;
  htim15.Init.Prescaler = 0;
  htim15.Init.CounterMode = TIM_COUNTERMODE_UP;
  htim15.Init.Period = 65535;
  htim15.Init.ClockDivision = TIM_CLOCKDIVISION_DIV1;
  htim15.Init.RepetitionCounter = 0;
  htim15.Init.AutoReloadPreload = TIM_AUTORELOAD_PRELOAD_DISABLE;
  if (HAL_TIM_PWM_Init(&htim15) != HAL_OK)
  {
    Error_Handler();
  }
  sMasterConfig.MasterOutputTrigger = TIM_TRGO_RESET;
  sMasterConfig.MasterSlaveMode = TIM_MASTERSLAVEMODE_DISABLE;
  if (HAL_TIMEx_MasterConfigSynchronization(&htim15, &sMasterConfig) != HAL_OK)
  {
    Error_Handler();
  }
  sConfigOC.OCMode = TIM_OCMODE_PWM1;
  sConfigOC.Pulse = 0;
  sConfigOC.OCPolarity = TIM_OCPOLARITY_HIGH;
  sConfigOC.OCNPolarity = TIM_OCNPOLARITY_HIGH;
  sConfigOC.OCFastMode = TIM_OCFAST_DISABLE;
  sConfigOC.OCIdleState = TIM_OCIDLESTATE_RESET;
  sConfigOC.OCNIdleState = TIM_OCNIDLESTATE_RESET;
  if (HAL_TIM_PWM_ConfigChannel(&htim15, &sConfigOC, TIM_CHANNEL_1) != HAL_OK)
  {
    Error_Handler();
  }
  sBreakDeadTimeConfig.OffStateRunMode = TIM_OSSR_DISABLE;
  sBreakDeadTimeConfig.OffStateIDLEMode = TIM_OSSI_DISABLE;
  sBreakDeadTimeConfig.LockLevel = TIM_LOCKLEVEL_OFF;
  sBreakDeadTimeConfig.DeadTime = 0;
  sBreakDeadTimeConfig.BreakState = TIM_BREAK_DISABLE;
  sBreakDeadTimeConfig.BreakPolarity = TIM_BREAKPOLARITY_HIGH;
  sBreakDeadTimeConfig.BreakFilter = 0;
  sBreakDeadTimeConfig.AutomaticOutput = TIM_AUTOMATICOUTPUT_DISABLE;
  if (HAL_TIMEx_ConfigBreakDeadTime(&htim15, &sBreakDeadTimeConfig) != HAL_OK)
  {
    Error_Handler();
  }
  HAL_TIM_MspPostInit(&htim15);

}

static void MX_UART4_Init(void)
{

  huart4.Instance = UART4;
  huart4.Init.BaudRate = 500000;
  huart4.Init.WordLength = UART_WORDLENGTH_8B;
  huart4.Init.StopBits = UART_STOPBITS_1;
  huart4.Init.Parity = UART_PARITY_NONE;
  huart4.Init.Mode = UART_MODE_TX_RX;
  huart4.Init.HwFlowCtl = UART_HWCONTROL_NONE;
  huart4.Init.OverSampling = UART_OVERSAMPLING_16;
  huart4.Init.OneBitSampling = UART_ONE_BIT_SAMPLE_DISABLE;
  huart4.Init.ClockPrescaler = UART_PRESCALER_DIV1;
  huart4.AdvancedInit.AdvFeatureInit = UART_ADVFEATURE_NO_INIT;
  if (HAL_UART_Init(&huart4) != HAL_OK)
  {
    Error_Handler();
  }
  if (HAL_UARTEx_SetTxFifoThreshold(&huart4, UART_TXFIFO_THRESHOLD_1_8) != HAL_OK)
  {
    Error_Handler();
  }
  if (HAL_UARTEx_SetRxFifoThreshold(&huart4, UART_RXFIFO_THRESHOLD_1_8) != HAL_OK)
  {
    Error_Handler();
  }
  if (HAL_UARTEx_DisableFifoMode(&huart4) != HAL_OK)
  {
    Error_Handler();
  }

}

static void MX_UART8_Init(void)
{

  huart8.Instance = UART8;
  huart8.Init.BaudRate = 115200;
  huart8.Init.WordLength = UART_WORDLENGTH_8B;
  huart8.Init.StopBits = UART_STOPBITS_1;
  huart8.Init.Parity = UART_PARITY_NONE;
  huart8.Init.Mode = UART_MODE_TX_RX;
  huart8.Init.HwFlowCtl = UART_HWCONTROL_NONE;
  huart8.Init.OverSampling = UART_OVERSAMPLING_16;
  huart8.Init.OneBitSampling = UART_ONE_BIT_SAMPLE_DISABLE;
  huart8.Init.ClockPrescaler = UART_PRESCALER_DIV1;
  huart8.AdvancedInit.AdvFeatureInit = UART_ADVFEATURE_NO_INIT;
  if (HAL_UART_Init(&huart8) != HAL_OK)
  {
    Error_Handler();
  }
  if (HAL_UARTEx_SetTxFifoThreshold(&huart8, UART_TXFIFO_THRESHOLD_1_8) != HAL_OK)
  {
    Error_Handler();
  }
  if (HAL_UARTEx_SetRxFifoThreshold(&huart8, UART_RXFIFO_THRESHOLD_1_8) != HAL_OK)
  {
    Error_Handler();
  }
  if (HAL_UARTEx_DisableFifoMode(&huart8) != HAL_OK)
  {
    Error_Handler();
  }

}

static void MX_USART2_UART_Init(void)
{

  huart2.Instance = USART2;
  huart2.Init.BaudRate = 115200;
  huart2.Init.WordLength = UART_WORDLENGTH_8B;
  huart2.Init.StopBits = UART_STOPBITS_1;
  huart2.Init.Parity = UART_PARITY_NONE;
  huart2.Init.Mode = UART_MODE_TX_RX;
  huart2.Init.HwFlowCtl = UART_HWCONTROL_NONE;
  huart2.Init.OverSampling = UART_OVERSAMPLING_16;
  huart2.Init.OneBitSampling = UART_ONE_BIT_SAMPLE_DISABLE;
  huart2.Init.ClockPrescaler = UART_PRESCALER_DIV1;
  huart2.AdvancedInit.AdvFeatureInit = UART_ADVFEATURE_NO_INIT;
  if (HAL_UART_Init(&huart2) != HAL_OK)
  {
    Error_Handler();
  }
  if (HAL_UARTEx_SetTxFifoThreshold(&huart2, UART_TXFIFO_THRESHOLD_1_8) != HAL_OK)
  {
    Error_Handler();
  }
  if (HAL_UARTEx_SetRxFifoThreshold(&huart2, UART_RXFIFO_THRESHOLD_1_8) != HAL_OK)
  {
    Error_Handler();
  }
  if (HAL_UARTEx_DisableFifoMode(&huart2) != HAL_OK)
  {
    Error_Handler();
  }

}

static void MX_DMA_Init(void)
{

  /* DMA controller clock enable */
  __HAL_RCC_DMA1_CLK_ENABLE();

  /* DMA interrupt init */
  /* DMA1_Stream0_IRQn interrupt configuration */
  HAL_NVIC_SetPriority(DMA1_Stream0_IRQn, 5, 0);
  HAL_NVIC_EnableIRQ(DMA1_Stream0_IRQn);
  /* DMA1_Stream1_IRQn interrupt configuration */
  HAL_NVIC_SetPriority(DMA1_Stream1_IRQn, 5, 0);
  HAL_NVIC_EnableIRQ(DMA1_Stream1_IRQn);
  /* DMA1_Stream2_IRQn interrupt configuration */
  HAL_NVIC_SetPriority(DMA1_Stream2_IRQn, 5, 0);
  HAL_NVIC_EnableIRQ(DMA1_Stream2_IRQn);
  /* DMA1_Stream3_IRQn interrupt configuration */
  HAL_NVIC_SetPriority(DMA1_Stream3_IRQn, 5, 0);
  HAL_NVIC_EnableIRQ(DMA1_Stream3_IRQn);
  /* DMA1_Stream4_IRQn interrupt configuration */
  HAL_NVIC_SetPriority(DMA1_Stream4_IRQn, 5, 0);
  HAL_NVIC_EnableIRQ(DMA1_Stream4_IRQn);
  /* DMA1_Stream5_IRQn interrupt configuration */
  HAL_NVIC_SetPriority(DMA1_Stream5_IRQn, 5, 0);
  HAL_NVIC_EnableIRQ(DMA1_Stream5_IRQn);

}

static void MX_GPIO_Init(void)
{
  GPIO_InitTypeDef GPIO_InitStruct = {0};

  /* GPIO Ports Clock Enable */
  __HAL_RCC_GPIOE_CLK_ENABLE();
  __HAL_RCC_GPIOI_CLK_ENABLE();
  __HAL_RCC_GPIOC_CLK_ENABLE();
  __HAL_RCC_GPIOF_CLK_ENABLE();
  __HAL_RCC_GPIOH_CLK_ENABLE();
  __HAL_RCC_GPIOA_CLK_ENABLE();
  __HAL_RCC_GPIOB_CLK_ENABLE();
  __HAL_RCC_GPIOJ_CLK_ENABLE();
  __HAL_RCC_GPIOG_CLK_ENABLE();
  __HAL_RCC_GPIOD_CLK_ENABLE();
  __HAL_RCC_GPIOK_CLK_ENABLE();

  /*Configure GPIO pin Output Level */
  HAL_GPIO_WritePin(GPIOE, RELAY_HS_Pin|BMS_NO_FLT_Pin|LED2_Pin, GPIO_PIN_RESET);

  /*Configure GPIO pin Output Level */
  HAL_GPIO_WritePin(GPIOI, RELAY_LS_Pin|RELAY_DISCHARGE_Pin|PSM_CS_0_Pin, GPIO_PIN_RESET);

  /*Configure GPIO pin Output Level */
  HAL_GPIO_WritePin(RELAY_PRECHARGE_GPIO_Port, RELAY_PRECHARGE_Pin, GPIO_PIN_RESET);

  /*Configure GPIO pin Output Level */
  HAL_GPIO_WritePin(GPIOA, left_indicator_Pin|right_indicator_Pin, GPIO_PIN_RESET);

  /*Configure GPIO pin Output Level */
  HAL_GPIO_WritePin(BMS_WKUP_GPIO_Port, BMS_WKUP_Pin, GPIO_PIN_RESET);

  /*Configure GPIO pin Output Level */
  HAL_GPIO_WritePin(GPIOH, LED0_Pin|LED1_Pin, GPIO_PIN_RESET);

  /*Configure GPIO pin Output Level */
  HAL_GPIO_WritePin(PSM_LVDS_EN_GPIO_Port, PSM_LVDS_EN_Pin, GPIO_PIN_RESET);

  /*Configure GPIO pin Output Level */
  HAL_GPIO_WritePin(GPIOK, TMC5160_CS0_Pin|PSM_DReady_Pin|HORN_EN_Pin|TMC5160_CS1_Pin
                          |Light_ctrl_PWR_EN_Pin, GPIO_PIN_RESET);

  /*Configure GPIO pin Output Level */
  HAL_GPIO_WritePin(GPIOG, PSM_CS_1_Pin|PSM_CS_3_Pin|PSM_CS_2_Pin, GPIO_PIN_RESET);

  /*Configure GPIO pins : PE2 PE4 PE6 PE7
                           PE8 PE10 PE11 PE13
                           PE15 PE0 PE1 */
  GPIO_InitStruct.Pin = GPIO_PIN_2|GPIO_PIN_4|GPIO_PIN_6|GPIO_PIN_7
                          |GPIO_PIN_8|GPIO_PIN_10|GPIO_PIN_11|GPIO_PIN_13
                          |GPIO_PIN_15|GPIO_PIN_0|GPIO_PIN_1;
  GPIO_InitStruct.Mode = GPIO_MODE_ANALOG;
  GPIO_InitStruct.Pull = GPIO_NOPULL;
  HAL_GPIO_Init(GPIOE, &GPIO_InitStruct);

  /*Configure GPIO pins : RELAY_HS_Pin BMS_NO_FLT_Pin LED2_Pin */
  GPIO_InitStruct.Pin = RELAY_HS_Pin|BMS_NO_FLT_Pin|LED2_Pin;
  GPIO_InitStruct.Mode = GPIO_MODE_OUTPUT_PP;
  GPIO_InitStruct.Pull = GPIO_NOPULL;
  GPIO_InitStruct.Speed = GPIO_SPEED_FREQ_LOW;
  HAL_GPIO_Init(GPIOE, &GPIO_InitStruct);

  /*Configure GPIO pins : PI8 PI10 PI11 PI14
                           PI15 PI4 PI5 PI6
                           PI7 */
  GPIO_InitStruct.Pin = GPIO_PIN_8|GPIO_PIN_10|GPIO_PIN_11|GPIO_PIN_14
                          |GPIO_PIN_15|GPIO_PIN_4|GPIO_PIN_5|GPIO_PIN_6
                          |GPIO_PIN_7;
  GPIO_InitStruct.Mode = GPIO_MODE_ANALOG;
  GPIO_InitStruct.Pull = GPIO_NOPULL;
  HAL_GPIO_Init(GPIOI, &GPIO_InitStruct);

  /*Configure GPIO pins : PC13 PC14 PC15 PC0
                           PC1 PC2 PC3 PC4
                           PC5 PC6 PC7 PC8
                           PC9 PC10 PC11 PC12 */
  GPIO_InitStruct.Pin = GPIO_PIN_13|GPIO_PIN_14|GPIO_PIN_15|GPIO_PIN_0
                          |GPIO_PIN_1|GPIO_PIN_2|GPIO_PIN_3|GPIO_PIN_4
                          |GPIO_PIN_5|GPIO_PIN_6|GPIO_PIN_7|GPIO_PIN_8
                          |GPIO_PIN_9|GPIO_PIN_10|GPIO_PIN_11|GPIO_PIN_12;
  GPIO_InitStruct.Mode = GPIO_MODE_ANALOG;
  GPIO_InitStruct.Pull = GPIO_NOPULL;
  HAL_GPIO_Init(GPIOC, &GPIO_InitStruct);

  /*Configure GPIO pins : RELAY_LS_Pin PSM_CS_0_Pin */
  GPIO_InitStruct.Pin = RELAY_LS_Pin|PSM_CS_0_Pin;
  GPIO_InitStruct.Mode = GPIO_MODE_OUTPUT_PP;
  GPIO_InitStruct.Pull = GPIO_NOPULL;
  GPIO_InitStruct.Speed = GPIO_SPEED_FREQ_LOW;
  HAL_GPIO_Init(GPIOI, &GPIO_InitStruct);

  /*Configure GPIO pins : PF0 PF1 PF3 PF4
                           PF5 PF6 PF7 PF8
                           PF9 PF10 PF11 PF12
                           PF13 PF14 PF15 */
  GPIO_InitStruct.Pin = GPIO_PIN_0|GPIO_PIN_1|GPIO_PIN_3|GPIO_PIN_4
                          |GPIO_PIN_5|GPIO_PIN_6|GPIO_PIN_7|GPIO_PIN_8
                          |GPIO_PIN_9|GPIO_PIN_10|GPIO_PIN_11|GPIO_PIN_12
                          |GPIO_PIN_13|GPIO_PIN_14|GPIO_PIN_15;
  GPIO_InitStruct.Mode = GPIO_MODE_ANALOG;
  GPIO_InitStruct.Pull = GPIO_NOPULL;
  HAL_GPIO_Init(GPIOF, &GPIO_InitStruct);

  /*Configure GPIO pin : RELAY_PRECHARGE_Pin */
  GPIO_InitStruct.Pin = RELAY_PRECHARGE_Pin;
  GPIO_InitStruct.Mode = GPIO_MODE_OUTPUT_PP;
  GPIO_InitStruct.Pull = GPIO_NOPULL;
  GPIO_InitStruct.Speed = GPIO_SPEED_FREQ_LOW;
  HAL_GPIO_Init(RELAY_PRECHARGE_GPIO_Port, &GPIO_InitStruct);

  /*Configure GPIO pin : ESD_DETECT_Pin */
  GPIO_InitStruct.Pin = ESD_DETECT_Pin;
  GPIO_InitStruct.Mode = GPIO_MODE_INPUT;
  GPIO_InitStruct.Pull = GPIO_NOPULL;
  HAL_GPIO_Init(ESD_DETECT_GPIO_Port, &GPIO_InitStruct);

  /*Configure GPIO pin : RELAY_DISCHARGE_Pin */
  GPIO_InitStruct.Pin = RELAY_DISCHARGE_Pin;
  GPIO_InitStruct.Mode = GPIO_MODE_OUTPUT_PP;
  GPIO_InitStruct.Pull = GPIO_PULLDOWN;
  GPIO_InitStruct.Speed = GPIO_SPEED_FREQ_LOW;
  HAL_GPIO_Init(RELAY_DISCHARGE_GPIO_Port, &GPIO_InitStruct);

  /*Configure GPIO pins : left_indicator_Pin right_indicator_Pin */
  GPIO_InitStruct.Pin = left_indicator_Pin|right_indicator_Pin;
  GPIO_InitStruct.Mode = GPIO_MODE_OUTPUT_PP;
  GPIO_InitStruct.Pull = GPIO_NOPULL;
  GPIO_InitStruct.Speed = GPIO_SPEED_FREQ_LOW;
  HAL_GPIO_Init(GPIOA, &GPIO_InitStruct);

  /*Configure GPIO pins : PH2 PH3 PH4 PH5
                           PH7 PH8 PH12 PH13
                           PH14 PH15 */
  GPIO_InitStruct.Pin = GPIO_PIN_2|GPIO_PIN_3|GPIO_PIN_4|GPIO_PIN_5
                          |GPIO_PIN_7|GPIO_PIN_8|GPIO_PIN_12|GPIO_PIN_13
                          |GPIO_PIN_14|GPIO_PIN_15;
  GPIO_InitStruct.Mode = GPIO_MODE_ANALOG;
  GPIO_InitStruct.Pull = GPIO_NOPULL;
  HAL_GPIO_Init(GPIOH, &GPIO_InitStruct);

  /*Configure GPIO pins : PA4 PA5 PA7 PA8
                           PA9 PA10 PA15 */
  GPIO_InitStruct.Pin = GPIO_PIN_4|GPIO_PIN_5|GPIO_PIN_7|GPIO_PIN_8
                          |GPIO_PIN_9|GPIO_PIN_10|GPIO_PIN_15;
  GPIO_InitStruct.Mode = GPIO_MODE_ANALOG;
  GPIO_InitStruct.Pull = GPIO_NOPULL;
  HAL_GPIO_Init(GPIOA, &GPIO_InitStruct);

  /*Configure GPIO pins : PB0 PB1 PB2 PB10
                           PB11 PB12 PB14 PB15
                           PB3 PB4 PB5 PB6
                           PB7 PB8 PB9 */
  GPIO_InitStruct.Pin = GPIO_PIN_0|GPIO_PIN_1|GPIO_PIN_2|GPIO_PIN_10
                          |GPIO_PIN_11|GPIO_PIN_12|GPIO_PIN_14|GPIO_PIN_15
                          |GPIO_PIN_3|GPIO_PIN_4|GPIO_PIN_5|GPIO_PIN_6
                          |GPIO_PIN_7|GPIO_PIN_8|GPIO_PIN_9;
  GPIO_InitStruct.Mode = GPIO_MODE_ANALOG;
  GPIO_InitStruct.Pull = GPIO_NOPULL;
  HAL_GPIO_Init(GPIOB, &GPIO_InitStruct);

  /*Configure GPIO pins : PJ0 PJ1 PJ2 PJ3
                           PJ12 PJ13 PJ14 PJ15 */
  GPIO_InitStruct.Pin = GPIO_PIN_0|GPIO_PIN_1|GPIO_PIN_2|GPIO_PIN_3
                          |GPIO_PIN_12|GPIO_PIN_13|GPIO_PIN_14|GPIO_PIN_15;
  GPIO_InitStruct.Mode = GPIO_MODE_ANALOG;
  GPIO_InitStruct.Pull = GPIO_NOPULL;
  HAL_GPIO_Init(GPIOJ, &GPIO_InitStruct);

  /*Configure GPIO pins : BMS_FLT_Pin TMC5160_DIAG1_Pin TMC5160_DIAG0_Pin */
  GPIO_InitStruct.Pin = BMS_FLT_Pin|TMC5160_DIAG1_Pin|TMC5160_DIAG0_Pin;
  GPIO_InitStruct.Mode = GPIO_MODE_INPUT;
  GPIO_InitStruct.Pull = GPIO_NOPULL;
  HAL_GPIO_Init(GPIOJ, &GPIO_InitStruct);

  /*Configure GPIO pins : PG0 PG1 PG5 PG6
                           PG7 PG8 PG9 PG10
                           PG11 PG12 PG13 PG14
                           PG15 */
  GPIO_InitStruct.Pin = GPIO_PIN_0|GPIO_PIN_1|GPIO_PIN_5|GPIO_PIN_6
                          |GPIO_PIN_7|GPIO_PIN_8|GPIO_PIN_9|GPIO_PIN_10
                          |GPIO_PIN_11|GPIO_PIN_12|GPIO_PIN_13|GPIO_PIN_14
                          |GPIO_PIN_15;
  GPIO_InitStruct.Mode = GPIO_MODE_ANALOG;
  GPIO_InitStruct.Pull = GPIO_NOPULL;
  HAL_GPIO_Init(GPIOG, &GPIO_InitStruct);

  /*Configure GPIO pin : BMS_WKUP_Pin */
  GPIO_InitStruct.Pin = BMS_WKUP_Pin;
  GPIO_InitStruct.Mode = GPIO_MODE_OUTPUT_PP;
  GPIO_InitStruct.Pull = GPIO_NOPULL;
  GPIO_InitStruct.Speed = GPIO_SPEED_FREQ_LOW;
  HAL_GPIO_Init(BMS_WKUP_GPIO_Port, &GPIO_InitStruct);

  /*Configure GPIO pins : LED0_Pin LED1_Pin */
  GPIO_InitStruct.Pin = LED0_Pin|LED1_Pin;
  GPIO_InitStruct.Mode = GPIO_MODE_OUTPUT_PP;
  GPIO_InitStruct.Pull = GPIO_NOPULL;
  GPIO_InitStruct.Speed = GPIO_SPEED_FREQ_LOW;
  HAL_GPIO_Init(GPIOH, &GPIO_InitStruct);

  /*Configure GPIO pin : PSM_LVDS_EN_Pin */
  GPIO_InitStruct.Pin = PSM_LVDS_EN_Pin;
  GPIO_InitStruct.Mode = GPIO_MODE_OUTPUT_PP;
  GPIO_InitStruct.Pull = GPIO_NOPULL;
  GPIO_InitStruct.Speed = GPIO_SPEED_FREQ_LOW;
  HAL_GPIO_Init(PSM_LVDS_EN_GPIO_Port, &GPIO_InitStruct);

  /*Configure GPIO pins : PD8 PD9 PD10 PD11
                           PD12 PD13 PD14 PD15
                           PD0 PD1 PD2 PD3
                           PD4 PD5 PD6 PD7 */
  GPIO_InitStruct.Pin = GPIO_PIN_8|GPIO_PIN_9|GPIO_PIN_10|GPIO_PIN_11
                          |GPIO_PIN_12|GPIO_PIN_13|GPIO_PIN_14|GPIO_PIN_15
                          |GPIO_PIN_0|GPIO_PIN_1|GPIO_PIN_2|GPIO_PIN_3
                          |GPIO_PIN_4|GPIO_PIN_5|GPIO_PIN_6|GPIO_PIN_7;
  GPIO_InitStruct.Mode = GPIO_MODE_ANALOG;
  GPIO_InitStruct.Pull = GPIO_NOPULL;
  HAL_GPIO_Init(GPIOD, &GPIO_InitStruct);

  /*Configure GPIO pins : TMC5160_CS0_Pin PSM_DReady_Pin TMC5160_CS1_Pin Light_ctrl_PWR_EN_Pin */
  GPIO_InitStruct.Pin = TMC5160_CS0_Pin|PSM_DReady_Pin|TMC5160_CS1_Pin|Light_ctrl_PWR_EN_Pin;
  GPIO_InitStruct.Mode = GPIO_MODE_OUTPUT_PP;
  GPIO_InitStruct.Pull = GPIO_NOPULL;
  GPIO_InitStruct.Speed = GPIO_SPEED_FREQ_LOW;
  HAL_GPIO_Init(GPIOK, &GPIO_InitStruct);

  /*Configure GPIO pins : PSM_CS_1_Pin PSM_CS_3_Pin PSM_CS_2_Pin */
  GPIO_InitStruct.Pin = PSM_CS_1_Pin|PSM_CS_3_Pin|PSM_CS_2_Pin;
  GPIO_InitStruct.Mode = GPIO_MODE_OUTPUT_PP;
  GPIO_InitStruct.Pull = GPIO_NOPULL;
  GPIO_InitStruct.Speed = GPIO_SPEED_FREQ_LOW;
  HAL_GPIO_Init(GPIOG, &GPIO_InitStruct);

  /*Configure GPIO pin : HORN_EN_Pin */
  GPIO_InitStruct.Pin = HORN_EN_Pin;
  GPIO_InitStruct.Mode = GPIO_MODE_OUTPUT_PP;
  GPIO_InitStruct.Pull = GPIO_PULLDOWN;
  GPIO_InitStruct.Speed = GPIO_SPEED_FREQ_LOW;
  HAL_GPIO_Init(HORN_EN_GPIO_Port, &GPIO_InitStruct);

  /*Configure GPIO pins : PK6 PK7 */
  GPIO_InitStruct.Pin = GPIO_PIN_6|GPIO_PIN_7;
  GPIO_InitStruct.Mode = GPIO_MODE_ANALOG;
  GPIO_InitStruct.Pull = GPIO_NOPULL;
  HAL_GPIO_Init(GPIOK, &GPIO_InitStruct);

}

/* USER CODE BEGIN 4 */
void serialParse(B_tcpPacket_t *pkt){
	switch(pkt->senderID){
		case PPTMB_ID: //Parse data from PPTMB
			if (pkt->data[0] == PPTMB_RELAYS_STATE_ID){ //Update relay state from PPTMB
				vTaskSuspendAll();	relay.array_relay_state = pkt->data[3];	xTaskResumeAll();
			}
			if (pkt->data[0] == PPTMB_BUS_METRICS_ID){
				vTaskSuspendAll();
				sfq_push(&array_overcurrent_queue, fabs(arrayToFloat(&(pkt->data[8]))));
				xTaskResumeAll();
			}
			break;

		case DCMB_ID: //Parse data from DCMB
			//HAL_UART_Transmit(&huart2, (uint8_t*)buf, sizeof(buf), 100);
			//Light control
			if (pkt->data[0] == DCMB_LIGHTCONTROL_ID){
				lightInstruction = pkt->data[1];
				xQueueSend(lightsCtrl, &lightInstruction, 10); //Send to lights control task

			//Relays
			} else if (pkt->data[0] == DCMB_RELAYS_STATE_ID){
				if ((pkt->data[2] == OPEN) && (relay.battery_relay_state == CLOSED)){ //Open relays and resend
					relayCtrlMessage = RELAY_QUEUE_OPEN_BATTERY;
					xQueueSend(relayCtrl, &relayCtrlMessage, 10); //Open battery relays

				} else if ((pkt->data[2] == CLOSED) && (batteryState == HEALTHY) && (relay.battery_relay_state == OPEN)){ //Try to close relays
					relayCtrlMessage = RELAY_QUEUE_CLOSE_BATTERY;
					xQueueSend(relayCtrl, &relayCtrlMessage, 10); //Close battery relays
				}
				if ((pkt->data[3] == OPEN) && (relay.array_relay_state == CLOSED)){ //Open relays and resend
					relayCtrlMessage = RELAY_QUEUE_OPEN_ARRAY;
					xQueueSend(relayCtrl, &relayCtrlMessage, 10); //Open array relays

				} else if ((pkt->data[3] == CLOSED) && (batteryState == HEALTHY) && (relay.array_relay_state == OPEN)){ //Try to close relays
					relayCtrlMessage = RELAY_QUEUE_CLOSE_ARRAY;
					xQueueSend(relayCtrl, &relayCtrlMessage, 10); //Close array relays
				}

			//Horn
			} else if (pkt->data[0] == DCMB_STEERING_WHEEL_ID){
				if ((pkt->data[2] & 0b00001000) >> 3){ //Turn on horn
					HAL_GPIO_WritePin(HORN_EN_GPIO_Port, HORN_EN_Pin, GPIO_PIN_SET);

				} else { //Turn off horn
					HAL_GPIO_WritePin(HORN_EN_GPIO_Port, HORN_EN_Pin, GPIO_PIN_RESET);
				}
			} else if(pkt->data[0] == DCMB_MOTOR_CONTROL_STATE_ID){
				motorState = pkt->data[1];
			}
			break;

		case BMS_ID: //Parse data from BMS (comes from btcp_bms)
			BMS_tick_count_last_packet = xTaskGetTickCount();

			//BMS temperature
			if (pkt->data[0] == BMS_CELL_TEMP_ID){
				//Re-send on main bus
				B_tcpSend(btcp_main, pkt->data, pkt->length);

				//Check for overtemperature for each cell and call routine when battery has faulted
				for (int i = 0; i < NUM_TEMP_SENSORS_PER_MODULE; i++){ //3 thermistors
					uint8_t j = pkt->data[1]*NUM_TEMP_SENSORS_PER_MODULE + i;
					if (j < NUM_BATT_TEMP_SENSORS) {
						float temperature = arrayToFloat( &(pkt->data[4 * (i + 1)]) );
						battery_temperatures[j] = temperature;
					}
				}

			//BMS voltage
			} else if (pkt->data[0] == BMS_CELL_VOLT_ID){
				//Re-send on main bus
				B_tcpSend(btcp_main, pkt->data, pkt->length);

				//Check for over/undervoltage for each cell and call routine when battery has faulted
				for (int i = 0; i < NUM_CELLS_PER_MODULE; i++){ //5 cells
					uint8_t j = pkt->data[1]*NUM_CELLS_PER_MODULE + i;
					if (j < NUM_BATT_CELLS) {
						float voltage = arrayToFloat( &(pkt->data[4 * (i + 1)]) );
						battery_cell_voltages[j] = voltage;
					}
				}

				//Update global for discharge test
				if (pkt->data[1] == 0) cellUnderTestVoltage = arrayToFloat(&(pkt->data[4]));

			//BMS SoC
			} else if (pkt->data[0] == BMS_CELL_SOC_ID){
				//Re-send on main bus
				B_tcpSend(btcp_main, pkt->data, pkt->length);

				//Update global for discharge test (cell #0 of BMS #0)
				if (pkt->data[1] == 0) cellUnderTestSOC = arrayToFloat(&(pkt->data[4]));
			} else if (pkt->data[0] == BMS_HEARTBEAT_ID) {
				//RE-send on main bus
				B_tcpSend(btcp_main, pkt->data, pkt->length);
			}
			break;

		case CHASE_ID:
			if (pkt->data[0] == CHASE_LIGHTCONTROL_ID){
				xQueueSend(lightsCtrl, &(pkt->data[1]), 200); //Send to lights control task
			}
			if (pkt->data[0] == CHASE_FAULT_ENABLE_ID) {
				fault_enable = pkt->data[1];
				B_tcpSend(btcp_main, pkt->data, pkt->length);
			}
			break;

		case MCMB_ID:
			if (pkt->data[0] == MCMB_BUS_METRICS_ID){
				vTaskSuspendAll();
				sfq_push(&motor_overcurrent_queue, fabs(arrayToFloat(&(pkt->data[8]))));
				xTaskResumeAll();
			}
			if (pkt->data[0] == MCMB_MOTOR_TEMPERATURE_ID){
				motor_temperature = arrayToFloat(&(pkt->data[4]));
			}
			if (pkt->data[0] == MCMB_CAR_SPEED_ID){ //Car speed
				current_speed_kph = pkt->data[1];
			}
			break;
	}
}

// Responsible for opening and closing battery relays, and sending command to PPTMB to open and close array relays
void relayTask(void * argument){
	uint8_t buf_relay[10];

	for(;;){
		if (xQueueReceive(relayCtrl, &buf_relay, 200)){
			if (buf_relay[0] == RELAY_QUEUE_OPEN_BATTERY){
				relay.battery_relay_state = OPEN;

				uint8_t buf[2 * 4] = {BBMB_RELAYS_STATE_ID, batteryState, relay.battery_relay_state, relay.array_relay_state,
									  batteryFaultType, batteryFaultCell, batteryFaultTherm, 0};
				B_tcpSend(btcp_main, buf, sizeof(buf));
				open_relays(&relay);

				if (relay.array_relay_state == OPEN){ //Both battery and array relays are opened, so discharge HV bus
					HAL_GPIO_WritePin(relay.DISCHARGE_GPIO_Port, relay.DISCHARGE_Pin, GPIO_PIN_RESET);
					osDelay(DISCHARGE_TIME);
					HAL_GPIO_WritePin(relay.DISCHARGE_GPIO_Port, relay.DISCHARGE_Pin, GPIO_PIN_SET);
				}

			} else if (buf_relay[0] == RELAY_QUEUE_CLOSE_BATTERY){
				close_relays(&relay); // Note: we must close battery relay before PPTMB turns on mppt. Thus, close_relays() is called before B_tcpSend().
				relay.battery_relay_state = CLOSED;

				uint8_t buf[2 * 4] = {BBMB_RELAYS_STATE_ID, batteryState, relay.battery_relay_state, relay.array_relay_state,
									  batteryFaultType, batteryFaultCell, batteryFaultTherm, 0};
				B_tcpSend(btcp_main, buf, sizeof(buf));

			} else if (buf_relay[0] == RELAY_QUEUE_OPEN_ARRAY) {
				relay.array_relay_state = OPEN;
				uint8_t buf[2 * 4] = {BBMB_RELAYS_STATE_ID, batteryState, relay.battery_relay_state, relay.array_relay_state,
										batteryFaultType, batteryFaultCell, batteryFaultTherm, 0};
				B_tcpSend(btcp_main, buf, sizeof(buf));
				if (relay.battery_relay_state == OPEN){ //Both battery and array relays are opened, so discharge HV bus
					HAL_GPIO_WritePin(relay.DISCHARGE_GPIO_Port, relay.DISCHARGE_Pin, GPIO_PIN_RESET);
					osDelay(DISCHARGE_TIME);
					HAL_GPIO_WritePin(relay.DISCHARGE_GPIO_Port, relay.DISCHARGE_Pin, GPIO_PIN_SET);
				}

			} else if (buf_relay[0] == RELAY_QUEUE_CLOSE_ARRAY) {
				relay.array_relay_state = CLOSED;
				uint8_t buf[2 * 4] = {BBMB_RELAYS_STATE_ID, batteryState, relay.battery_relay_state, relay.array_relay_state,
										batteryFaultType, batteryFaultCell, batteryFaultTherm, 0};
				B_tcpSend(btcp_main, buf, sizeof(buf));
			}
		}
	}
}

// Broadcasts battery relay state at constant intervals
// This is a safety feature to ensure the rest of the car knows the battery relay state, even if one message is lost
void RelayStateTimer(xTimerHandle xTimer) {
	uint8_t buf[2 * 4] = {BBMB_RELAYS_STATE_ID, batteryState, relay.battery_relay_state, relay.array_relay_state,
										  batteryFaultType, batteryFaultCell, batteryFaultTherm, 0};
	B_tcpSend(btcp_main, buf, sizeof(buf));
}

void indicatorTimer(TimerHandle_t xTimer) {
	if (left_indicator_on && !hazard_on) {
		HAL_GPIO_TogglePin(left_indicator_GPIO_Port, left_indicator_Pin);
	} else if (right_indicator_on && !hazard_on) {
		HAL_GPIO_TogglePin(right_indicator_GPIO_Port, right_indicator_Pin);
	} else if (hazard_on) {
		HAL_GPIO_TogglePin(left_indicator_GPIO_Port, left_indicator_Pin);
		HAL_GPIO_WritePin(right_indicator_GPIO_Port, right_indicator_Pin, HAL_GPIO_ReadPin(left_indicator_GPIO_Port, left_indicator_Pin));
	} else if (!left_indicator_on && !hazard_on) {
		HAL_GPIO_WritePin(left_indicator_GPIO_Port, left_indicator_Pin, GPIO_PIN_RESET);
	} else if (!right_indicator_on && !hazard_on) {
		HAL_GPIO_WritePin(right_indicator_GPIO_Port, right_indicator_Pin, GPIO_PIN_RESET);
	}
}

void lightsTask(void * argument){
	uint8_t buf_get[10];
	float indicator_brightness = 0.20; //Don't go over 40%
	float DRL_brightness = 0.20; //Don't go over 50%
	float brake_brightness = 0.20; //Don't go over 50%
	float hazard_brightness = 0.20; //Don't go over 50%
	float BPS_fault_brightness = 0.20; //Don't go over 50%
	uint8_t DRL_switch_is_on = 0;

/**
 * Item in control queue is 8-bit binary instruction
 * 7: empty
 * 6: Start / stop (1/0)
 * 5: Fault indicator
 * 4: Hazard lights (left and right indicator)
 * 3: Brake Lights
 * 2: DRL
 * 1: Indicator
 * 0: Specifies left / right (0/1) indicator
 *
 * 0100 0010
 */

  /* Infinite loop */
  for(;;){
	if (xQueueReceive(lightsCtrl, &buf_get, 200)){
		// HAL_GPIO_TogglePin(GPIOH, GPIO_PIN_6);
		uint8_t light_msg = buf_get[0];
		uint8_t light_id = light_msg & 0x3E;

		switch(light_id){ // mask 0b0011 1110 to isolate light
			case INDICATOR_LIGHTS: // Indicator
				if ((light_msg & 0x40) >> 6 == LIGHTS_OFF){ //Turn off
//					turn_off_indicators(&lightsPeriph, (int)(light_msg & 0x01)); // masking last bit for left or right
					if ((light_msg & 0x01) == LEFT) {
						left_indicator_on = 0;
					}
					if ((light_msg & 0x01) == RIGHT) {
						right_indicator_on = 0;
					}
				} else { //Turn on
//					turn_on_indicators(&lightsPeriph, (int)(light_msg & 0x01), indicator_brightness); // masking last bit for left or right
					if ((light_msg & 0x01) == LEFT) {
						left_indicator_on = 1;
					}
					if ((light_msg & 0x01) == RIGHT) {
						right_indicator_on = 1;
					}
				}
				break;

			case DRL_LIGHTS: // DRL
				if ((light_msg & 0x40) != 0x00){
					turn_on_DRL(&lightsPeriph, DRL_brightness);
					DRL_switch_is_on = 1;
				} else {
					if (motorState == OFF) {
						// Only allow DRL to turn off when motor is off
						turn_off_DRL(&lightsPeriph);
					}
					DRL_switch_is_on = 0;
				}
				break;

			case BRAKES_LIGHTS: // brake
				if ((light_msg & 0x40) != 0x00){
					turn_on_brake_lights(&lightsPeriph, brake_brightness);
				} else {
					turn_off_brake_lights(&lightsPeriph);
				}
				break;

			case HAZARD_LIGHTS: // hazard light
				if ((light_msg & 0x40) != 0x00){
//					turn_on_hazard_lights(&lightsPeriph, hazard_brightness);
					hazard_on = 1;
				} else {
//					turn_off_hazard_lights(&lightsPeriph);
					hazard_on = 0;
				}
				break;

			case FAULT_LIGHTS: // fault indicator - started by interrupt?
				if ((light_msg & 0x40) != 0x00){
					turn_on_fault_indicator(&lightsPeriph, BPS_fault_brightness);
				} else {
					turn_off_fault_indicator(&lightsPeriph);
				}
				break;

			default:
				break;
		}
	}

	// default light states
	// When in efficiency mode, if car speed > 40 km/h, DRL lights are controlled by DRL switch
	if (efficiency_mode_on && motorState != OFF && current_speed_kph > 40) {
		if (DRL_switch_is_on) {
			turn_on_DRL(&lightsPeriph, DRL_BRIGHTNESS_DIM);
		} else {
			turn_off_DRL(&lightsPeriph);
		}

	// If motor is on, turn on DRL lights to follow regulation
	} else if (motorState != OFF) {
		turn_on_DRL(&lightsPeriph, DRL_brightness);

	// If motor is off, turn off DRL lights if DRL switch is off
	} else if (motorState == OFF) {
		if (!DRL_switch_is_on) {
			turn_off_DRL(&lightsPeriph);
		}
	}
  }
}

void HeartbeatHandler(TimerHandle_t xTimer){
	//Send periodic heartbeat so we know the board is still running
	B_tcpSend(btcp_main, heartbeat, sizeof(heartbeat));
	heartbeat[1] = ~heartbeat[1]; //Toggle for next time
	//Heartbeat only accessed here so no need for mutex
}

void PSMTaskHandler(void * parameters){

	double voltage, current;

	int delay = pdMS_TO_TICKS(round(1000 / PSM_FIR_FILTER_SAMPLING_FREQ_BBMB));
	while (1){

		voltage = readPSM(&psmPeriph, VBUS, 3);
		current = readPSM(&psmPeriph, CURRENT, 3);

		vTaskSuspendAll();

		psmFilter.push(&psmFilter, (float) voltage, VOLTAGE_MEASUREMENT);
		psmFilter.push(&psmFilter, (float) current, CURRENT_MEASUREMENT);

		xTaskResumeAll();
		vTaskDelay(delay);
	}
}

void measurementSender(void* p){
	int delay = pdMS_TO_TICKS(PSM_SEND_INTERVAL);
	uint8_t battery_overcurrent_cnt = 0; //Variable to hold number of overcurrent faults detected to implement threshold to reduce sensitivity
	uint32_t time_last_overcurrent = 0;
	while (1) {
		uint8_t busMetrics_HV[3 * 4] = {0};
		busMetrics_HV[0] = BBMB_BUS_METRICS_ID;

		//Get HV average
		vTaskSuspendAll();
		float HV_voltage = psmFilter.get_average(&psmFilter, VOLTAGE_MEASUREMENT);
		float HV_current = psmFilter.get_average(&psmFilter, CURRENT_MEASUREMENT);

		//Update battery pack current global variable (used for BMS communication)
		battery_current = HV_current;

		sfq_push(&battery_overcurrent_queue, fabs(HV_current));

		xTaskResumeAll();

		floatToArray(HV_voltage, busMetrics_HV + 4); // fills 4 - 7 of busMetrics
		floatToArray(HV_current, busMetrics_HV + 8); // fills 8 - 11 of busMetrics

		B_tcpSend(btcp_main, busMetrics_HV, sizeof(busMetrics_HV));
		B_tcpSend(btcp_bms, busMetrics_HV, sizeof(busMetrics_HV));

		// if (fabs(battery_current) >= HV_BATT_OC_DISCHARGE){
		// 	if (battery_overcurrent_cnt == 0) {
		// 		battery_overcurrent_cnt++;
		// 		time_last_overcurrent = xTaskGetTickCount() * 1000 / configTICK_RATE_HZ;
		// 	} else {
		// 		uint32_t time_now = xTaskGetTickCount() * 1000 / configTICK_RATE_HZ;
		// 		if (time_now - time_last_overcurrent >= BATT_OVERCURRENT_CNT_RESET_TIME) {
		// 			battery_overcurrent_cnt = 0;
		// 		} else {
		// 			battery_overcurrent_cnt++;
		// 		}
		// 		time_last_overcurrent = time_now;
		// 	}
		// }
		// vTaskSuspendAll();
		// if (battery_overcurrent_cnt >= BATT_OVERCURRENT_CNT_THRESHOLD){ //Overcurrent protection --> Put car into safe state
		// 	battery_overcurrent = 1;
		// } else {
		// 	battery_overcurrent = 0;
		// }
		// xTaskResumeAll();

//	//LV
//		uint8_t busMetrics_LV[3 * 4] = {0};
//		busMetrics_LV[0] = BBMB_LP_BUS_METRICS_ID;
//
//		vTaskSuspendAll();
//		PSMRead(&psmPeriph, &hspi2, &huart2, 1, 2, 1, voltageCurrent_LV, 2);
//		xTaskResumeAll();
//
//		floatToArray((float) voltageCurrent_LV[0], busMetrics_LV + 4); // fills 4 - 7 of busMetrics
//		floatToArray((float) voltageCurrent_LV[1], busMetrics_LV + 8); // fills 16 - 19 of busMetrics
//
//		B_tcpSend(btcp_main, busMetrics_LV, sizeof(busMetrics_LV));
		vTaskDelay(delay);
	}
}

void dischargeTest(TimerHandle_t xTimer){
	//Used to output CSV-formatted strings on UART2 to test discharge characteristics
	char buf[100];

	sprintf(buf, "%f, %f, %f\n", battery_current, cellUnderTestVoltage, cellUnderTestSOC);
}

/*
 *  fault_type:
	0 is overtemperature
	1 is overvoltage
	2 is undervoltage
	3 is overcurrent

	fault_cell: Indicates which cell is faulted in under-/overvoltage (0 to 29)

	fault_thermistor: Indicates which thermistor is faulted in overtemperature (0 to 35)
 *
 */
void battery_faulted_routine(/*uint8_t fault_type, uint8_t fault_cell, uint8_t fault_thermistor*/){
	//Call this function when the battery has faulted (OV, UV, OT, OC)

	//Update globals (not done since we will set these outside the function)
//	vTaskSuspendAll();
//	batteryState = FAULTED;
//	batteryFaultType  = fault_type;
//	batteryFaultCell  = fault_cell;
//	batteryFaultTherm = fault_thermistor;
//	xTaskResumeAll();

	uint8_t strobe_light_EN_cmd = 0b01100000; //Start BPS strobe light

	//Open both battery and array relays, as per WSC regulation
	relayCtrlMessage = RELAY_QUEUE_OPEN_ARRAY;
	xQueueSend(relayCtrl, &relayCtrlMessage, 10);
	relayCtrlMessage = RELAY_QUEUE_OPEN_BATTERY;
	xQueueSend(relayCtrl, &relayCtrlMessage, 10);

	//Change BMS power from battery module to 12V supplemental (not needed for WSC)
	// HAL_GPIO_WritePin(BMS_WKUP_GPIO_Port, BMS_WKUP_Pin, GPIO_PIN_RESET);

	//BPS strobe light
	xQueueSend(lightsCtrl, &strobe_light_EN_cmd, 50); //Send to lights control task

	//BMS fault light and safe state pin
	HAL_GPIO_WritePin(BMS_NO_FLT_GPIO_Port, BMS_NO_FLT_Pin, GPIO_PIN_RESET);
}

void battery_unfaulted_routine() {
	//--- Battery ---/
	vTaskSuspendAll();
	batteryState = HEALTHY;
	batteryFaultType = BATTERY_FAULT_NONE; //Default to fault type 4, which doesn't correspond to any fault
	batteryFaultCell = 0;
	batteryFaultTherm = 0;
	battery_overvoltage = 0;
	battery_undervoltage = 0;
	battery_overtemperature = 0;
	battery_undertemperature = 0;
	xTaskResumeAll();

	uint8_t strobe_light_EN_cmd = 0b00100000; //Stop BPS strobe light

	//BPS strobe light
	xQueueSend(lightsCtrl, &strobe_light_EN_cmd, 50); //Send to lights control task

	//BMS fault light and safe state pin
	HAL_GPIO_WritePin(BMS_NO_FLT_GPIO_Port, BMS_NO_FLT_Pin, GPIO_PIN_SET);
}

void fault_state_setter(void* parameters) {
	uint8_t run_unfaulted_routine = 1;
	uint8_t run_faulted_routine = 1;

	// for each element in battery_cell_voltages[], stores time since overvoltage
	uint32_t overvoltage_period[NUM_BATT_CELLS] = {0};
	uint32_t time_last_overvoltage[NUM_BATT_CELLS] = {0};

	// for each element in battery_cell_voltages[], stores time since undervoltage
	uint32_t undervoltage_period[NUM_BATT_CELLS] = {0};
	uint32_t time_last_undervoltage[NUM_BATT_CELLS] = {0};

	while(1) {

		vTaskSuspendAll();
		for (int i = 0; i < NUM_BATT_CELLS; i++) {
			float voltage = battery_cell_voltages[i];
			if (voltage != BATTERY_CELL_VOLTAGES_FAKE_VALUE && voltage != BATTERY_CELL_VOLTAGES_INITIAL_VALUE) {
				if ((voltage > HV_BATT_OV_THRESHOLD)){
					uint32_t curr_time = xTaskGetTickCount() / pdMS_TO_TICKS(1);
					if (overvoltage_period[i] == 0) {
						overvoltage_period[i] = 1;
					} else {
						overvoltage_period[i] = overvoltage_period[i] + curr_time - time_last_overvoltage[i];
					}
					time_last_overvoltage[i] = curr_time;
					if (overvoltage_period[i] > HV_BATT_OV_DEBOUNCE_TIME) {
						battery_overvoltage = 1;
					}
				} else if (voltage < HV_BATT_UV_THRESHOLD){
					uint32_t curr_time = xTaskGetTickCount() / pdMS_TO_TICKS(1);
					if (undervoltage_period[i] == 0) {
						undervoltage_period[i] = 1;
					} else {
						undervoltage_period[i] = undervoltage_period[i] + curr_time - time_last_undervoltage[i];
					}
					time_last_undervoltage[i] = curr_time;
					if (undervoltage_period[i] > HV_BATT_UV_DEBOUNCE_TIME) {
						battery_undervoltage = 1;
					}
				} else {
					overvoltage_period[i] = 0;
					undervoltage_period[i] = 0;
				}
			}
		}
		for (int i = 0; i < NUM_BATT_TEMP_SENSORS; i++) {
			float temperature = battery_temperatures[i];
			if (temperature != BATTERY_TEMPERATURES_INITIAL_VALUE) {
				if (temperature > HV_BATT_OT_THRESHOLD) {
					battery_overtemperature = 1;
				} else if (temperature < HV_BATT_UT_THRESHOLD) {
					battery_undertemperature = 1;
				}
			}
		}

		if (sfq_get_avg(&battery_overcurrent_queue) > HV_BATT_OC_THRESHOLD
				|| sfq_get_avg(&motor_overcurrent_queue) > HV_BATT_OC_THRESHOLD
				|| sfq_get_avg(&array_overcurrent_queue) > HV_BATT_OC_THRESHOLD) {
			battery_overcurrent = 1;
		}

		if (motor_temperature > MOTOR_OT_THRESHOLD) {
			motor_overtemperature = 1;
		}

		xTaskResumeAll();

		if (fault_enable) {
			if (battery_overvoltage || battery_undervoltage || battery_overtemperature || battery_undertemperature
						|| battery_overcurrent || motor_overtemperature) {
				batteryState = FAULTED;
				if (run_faulted_routine) {
					battery_faulted_routine();
					run_faulted_routine = 0;
				}
				run_unfaulted_routine = 1;
			}
		}

		uint8_t buf[] = {BBMB_FAULT_STATE_ID, 0, 0, 0};
		buf[1] |= battery_overvoltage << 0;
		buf[1] |= battery_undervoltage << 1;
		buf[1] |= battery_overtemperature << 2;
		buf[1] |= battery_undertemperature << 3;
		buf[1] |= battery_overcurrent << 4;
		buf[1] |= motor_overtemperature << 5;
		B_tcpSend(btcp_main, buf, sizeof(buf));

		vTaskDelay(pdMS_TO_TICKS(BMS_READ_INTERVAL)); // Don't need to run faster since the voltages , current, and temperatures are not updated more frequently than this.
	}
}

/* USER CODE END 4 */

void StartDefaultTask(void const * argument)
{
  for(;;)
  {
    osDelay(1);
  }
}

void HAL_TIM_PeriodElapsedCallback(TIM_HandleTypeDef *htim)
{
  if (htim->Instance == TIM6) {
    HAL_IncTick();
  }
  /* USER CODE BEGIN Callback 1 */
  else if (htim == &htim7){
	  HAL_GPIO_TogglePin(LED1_GPIO_Port, LED1_Pin);
  }
  /* USER CODE END Callback 1 */
}

void Error_Handler(void)
{
  __disable_irq();
  while (1)
  {
  }
}
